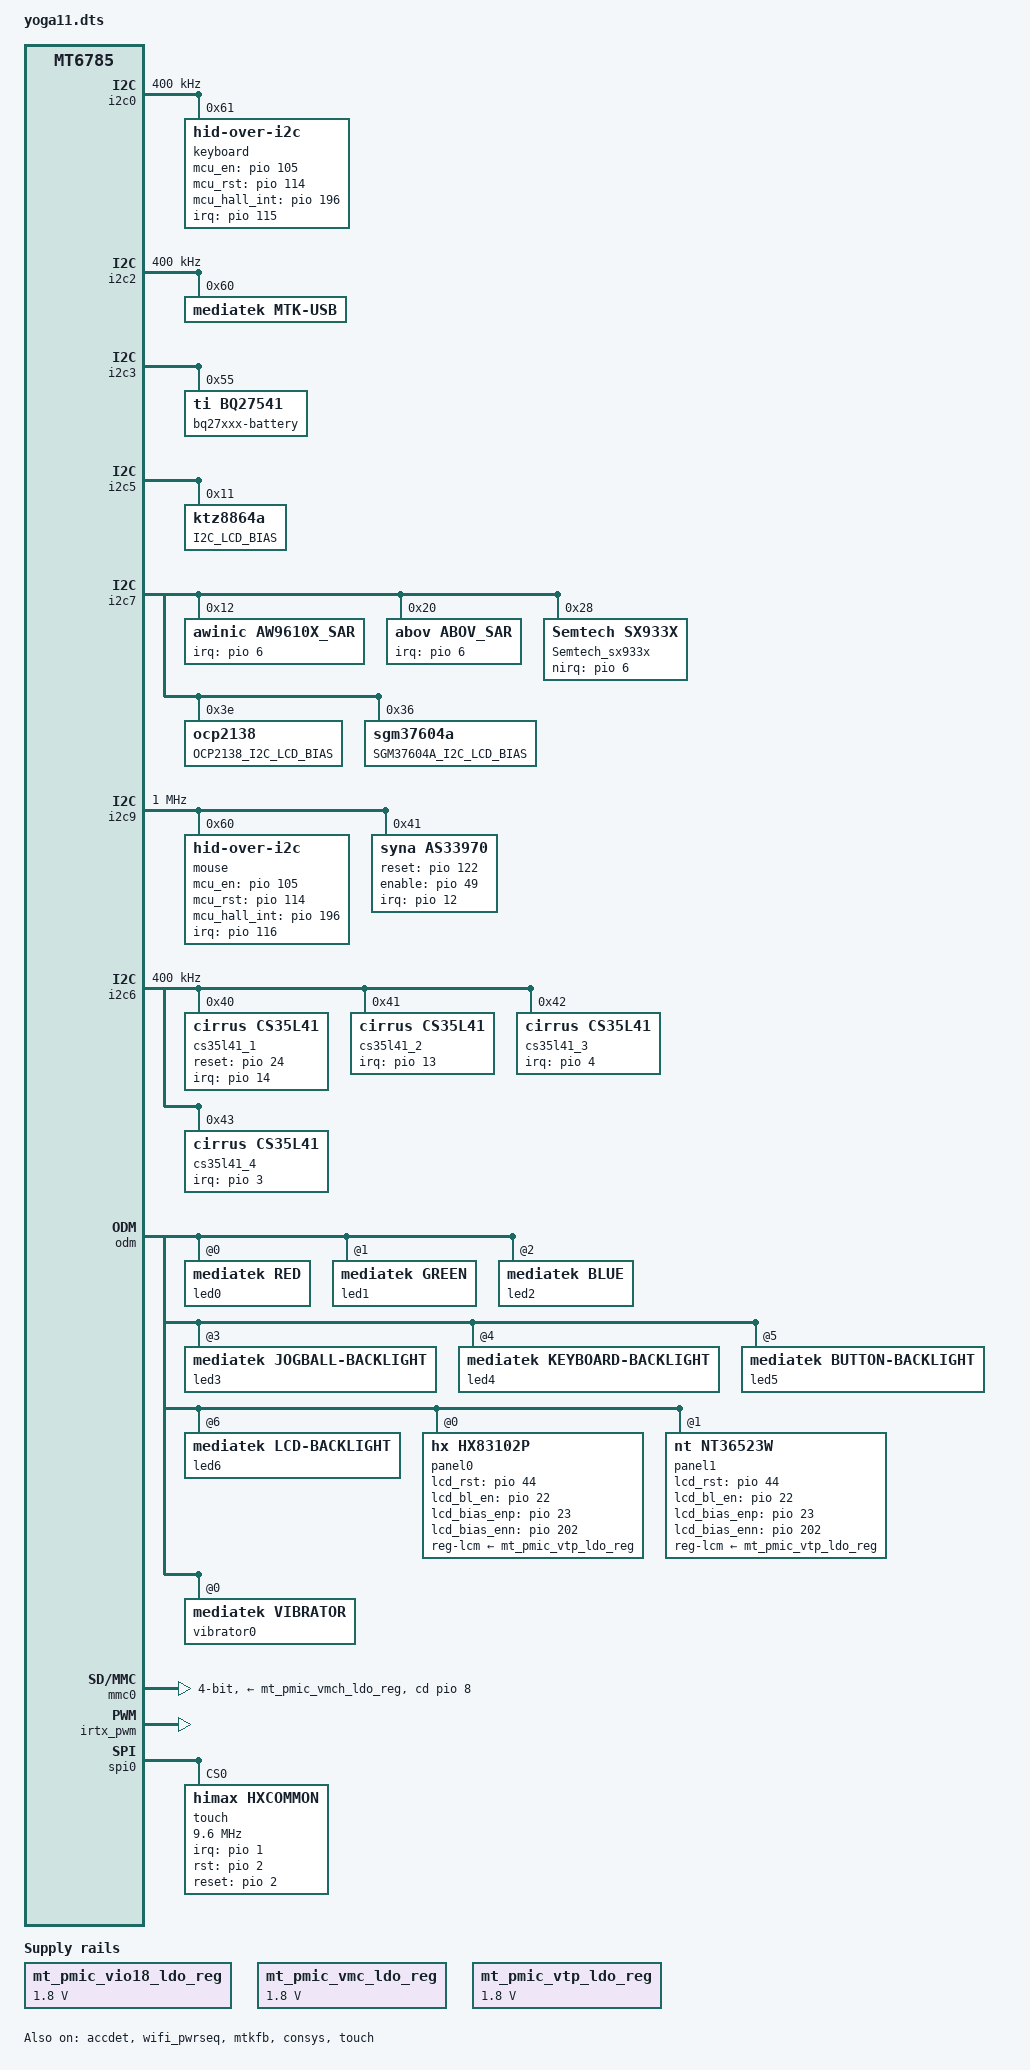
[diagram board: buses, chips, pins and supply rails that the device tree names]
/*
 * Copyright (C) 2015 MediaTek Inc.
 *
 * This program is free software: you can redistribute it and/or modify
 * it under the terms of the GNU General Public License version 2 as
 * published by the Free Software Foundation.
 *
 * This program is distributed in the hope that it will be useful,
 * but WITHOUT ANY WARRANTY; without even the implied warranty of
 * MERCHANTABILITY or FITNESS FOR A PARTICULAR PURPOSE. See the
 * GNU General Public License for more details.
 */
/dts-v1/;
/plugin/;
#include <dt-bindings/interrupt-controller/irq.h>
#include <dt-bindings/interrupt-controller/arm-gic.h>
#include <dt-bindings/pinctrl/mt6785-pinfunc.h>
#include <dt-bindings/clock/mt6785-clk.h>


&reserved_memory {
};

/* chosen */
&chosen {
	/* fpga may has no lk, we need to specify display info here */
	/* fb buffer is reserved using this dts by memory node above */

	atag,videolfb-fb_base_l = <0x7e605000>;
	atag,videolfb-fb_base_h = <0x0>;
	atag,videolfb-islcmfound = <1>;
	atag,videolfb-islcm_inited = <0>;
	atag,videolfb-fps= <6000>;
	atag,videolfb-vramSize= <0x017e8000>;
	atag,videolfb-lcmname=
		"hx83102p_fhdp_dsi_vdo_boe_drv";
};

&i2c0 {
	status="okay";
	clock-frequency = <400000>;
	keyboard@61 {
 		 compatible = "hid-over-i2c";
 		 reg = <0x61>;
 		 interrupt-parent = <&pio>;
		 interrupts = <115 IRQ_TYPE_EDGE_FALLING 115 0>;
 		 interrupt-names = "keyboard_kb_irq";
 		 hid-descr-addr =<0x0001>;
		 mcu_en_gpio = <&pio 105 0>;
		 mcu_rst_gpio = <&pio 114 0>;
		 mcu_hall_int_gpio = <&pio 196 0>;
		 post-power-on-delay-ms= <100>;
		 status = "okay";
 	};
};


&i2c2 {
	clock-frequency = <400000>;

	mtk-usb@60 {
		compatible = "mediatek,mtk-usb";
		reg = <0x60>;
		status = "okay";
	};
};

&i2c3 {
	bq27xxx-battery@55 {
		compatible = "ti,bq27541";
		reg = <0x55>;
	};
};

&lk_charger {
	compatible = "mediatek,lk_charger";
	fast_charge_voltage = <3000000>;
};

&charger {
	compatible = "mediatek,charger";
	/* PE */
	ta_12v_support;
	/* PD */
	pd_vbus_upper_bound = <11000000>;
};

&i2c5 {

	I2C_LCD_BIAS@11 {
		compatible = "ktz8864a" ;
		reg = <0x11> ;
		status = "okay" ;
	};
};


&i2c7 {
	aw9610x_sar@12 {
		compatible = "awinic,aw9610x_sar";
		reg = <0x12>;
		irq-gpio = <&pio 6 0x0>;
		chip_name = "AW96105";
		aw9610x,using-firmware;
		aw9610x,firmware_name = "aw9610x_wifi";
		status = "okay";
	};
	abov_sar@20 {
		compatible = "abov,abov_sar";
		reg = <0x20>;
		irq-gpio = <&pio 6 0x0>;        //interrup gpio number,based on actual circuit configuration
		reg_array_len = <0x03>;
		reg_array_val = <0x07 0x00 0x08 0x1B 0xFB 0x01>;
		cap,use_channel_ch0 = <0x00>;
		cap,use_channel_ch1 = <0x01>;
		cap,firmware_name = "AbovCapSenseWifi";  //firmware name,need pused AbovCapSense.BIN into /vendor/firmware/
		cap,channel_number = <0x02>;
		status = "okay";
	};
	Semtech_sx933x@28 {
		compatible = "Semtech,sx933x";
		reg = <0x28>;
		Semtech,nirq-gpio = <&pio 6 0x0>;
		/*use PH3/4 as the reference sensor*/
		/* set it to 0xff if the ref-phases-x is not used*/
		Semtech,ref-phases-a = <3>;
		Semtech,ref-phases-b = <4>;
		Semtech,reg-num = <85>;
		Semtech,reg-init = /bits/ 32 <
		0x8020 0x001F0000
		0x4004 0x00000070
		0x4008 0x00000000
		0x4054 0x00000400
		0x42C0 0x08000000
		0x42C4 0x0000003F
		0x800C 0x00000000
		0x8010 0x00000000
		0x8014 0x00000000
		0x8018 0x00000000
		0x801C 0x00000032
		0x8024 0x20000A8E
		0x8028 0x3FFE82E5
		0x802C 0x20000A8E
		0x8030 0x3FF7825F
		0x8034 0x20000A8E
		0x8038 0x3FBF82C4
		0x803C 0x20000A8E
		0x8040 0x3DFF8267
		0x8044 0x20000A8E
		0x8048 0x2FFF82E8
		0x804C 0x300004D4
		0x8050 0x00000000
		0x8054 0x0610FF00
		0x8058 0x20600018
		0x805C 0x2AD67000
		0x8060 0x00000000
		0x8064 0x00000000
		0x8068 0x00000000
		0x806C 0x00000000
		0x8070 0x00000000
		0x8074 0x10151C05
		0x8078 0x20600A0C
		0x807C 0x15EB8000
		0x8080 0x00000000
		0x8084 0x00000000
		0x8088 0x00000000
		0x808C 0x26002600
		0x8090 0x00010000
		0x8094 0x10252005
		0x8098 0x20600A0C
		0x809C 0x15EB8000
		0x80A0 0x00000000
		0x80A4 0x00000000
		0x80A8 0x00000000
		0x80AC 0x00270027
		0x80B0 0x00020000
		0x80B4 0x0650FF00
		0x80B8 0x20600018
		0x80BC 0x2AD67000
		0x80C0 0x00000000
		0x80C4 0x00000000
		0x80C8 0x00000000
		0x80CC 0x00000000
		0x80D0 0x00000000
		0x80D4 0x06500000
		0x80D8 0x20600018
		0x80DC 0x2AD67000
		0x80E0 0x00000000
		0x80E4 0x00000000
		0x80E8 0x00000000
		0x80EC 0x00000000
		0x80F0 0x00000000
		0x80F4 0x00100000
		0x80F8 0x20600C00
		0x80FC 0x00000000
		0x8100 0x00000000
		0x8104 0x00000000
		0x8108 0x00000000
		0x810C 0x00000000
		0x8110 0x00000000
		0x8124 0x04000004
		0x8128 0x04000003
		0x812C 0x00000000
		0x8130 0x00000000
		0x8134 0x00000000
		0x8138 0x00000000
		0x813C 0x00000000
		0x8140 0x00000000
		0x8144 0x00000000
		0x8148 0x00000000
		0x814C 0x00000000
		0x81A4 0x01D40010
		0x8020 0x001E001E
		0x4280 0x0000000F>;
	};
	OCP2138_I2C_LCD_BIAS@3E {
		compatible = "ocp2138" ;
		reg = <0x3E> ;
		status = "okay" ;
	};
	SGM37604A_I2C_LCD_BIAS@36 {
		compatible = "sgm37604a" ;
		reg = <0x36> ;
		status = "okay" ;
	};
};

&i2c9 {
	clock-frequency = <400000>;

	mouse@60 {
 		 compatible = "hid-over-i2c";
 		 reg = <0x60>;
		 mcu_en_gpio = <&pio 105 0>;
		 mcu_rst_gpio = <&pio 114 0>;
		 mcu_hall_int_gpio = <&pio 196 0>;
 		 interrupt-parent = <&pio>;
		 interrupts = <116 IRQ_TYPE_EDGE_FALLING 116 0>;
 		 interrupt-names = "keyboard_tp_irq";
 		 hid-descr-addr =<0x0001>;
		 post-power-on-delay-ms= <100>;
		 status = "okay";
	};
};


&i2c9 {
	clock-frequency = <1000000>;
	as33970@41 {
		compatible = "syna,as33970";
		reg = <0x41>;
		reset-gpios = <&pio 122 0x0>;
		enable-gpio = <&pio 49 0x0>;
		irq-gpios = <&pio 12 0x0>;
		status = "okay";
	};
};


&i2c6 {
	clock-frequency = <400000>;

	status="okay";

	/* Speaker 1st Amp */
	/*U2401  ---->  40*/
	cs35l41_1: cs35l41@40 {
		compatible = "cirrus,cs35l41";
		reg = <0x40>;

		reset-gpios = <&pio 24 0>;
		interrupt-parent = <&pio>;
		interrupts = <14 IRQ_TYPE_LEVEL_LOW 14 0>;
		interrupt-controller;
		#interrupt-cells = <2>;
		interrupt-names = "cs35l41_1_irq";

		pinctrl-names="default";
		pinctrl-0=<&cs35l41_1_irq_default>, <&cs35l41_reset_default>;

		cirrus,boost-peak-milliamp = <4500>;
		cirrus,boost-ind-nanohenry = <1000>;
		cirrus,boost-cap-microfarad = <15>;
		cirrus,asp-sdout-hiz = <0x3>;
		cirrus,fast-switch = "spk1_fast_switch1.txt", "spk1_fast_switch2.txt", "spk1_fast_switch3.txt", "spk1_fast_switch4.txt";
		cirrus,runtime-channel-switch;

		cirrus,gpio-config2 {
			cirrus,gpio-type = <1>; /* 0 indicate gpio, 1 indicate interrupt */
			cirrus,gpio-src-select = <0x4>;
			cirrus,gpio-output-enable;
		};
		adsps {
			#address-cells = <1>;
			#size-cells = <0>;
			adsp@2b80000 {
				reg = <0x2b80000>;
				firmware {
					protection {
						cirrus,full-name;
						cirrus,wmfw-file = "cs35l41-dsp1-spk-prot.wmfw";
						cirrus,bin-file = "cs35l41-dsp1-spk-prot1.bin";
					};
					calibration {
						cirrus,full-name;
						cirrus,wmfw-file = "cs35l41-dsp1-spk-cali.wmfw";
						cirrus,bin-file = "cs35l41-dsp1-spk-cali1.bin";
					};
				};
			};
		};
	};

	/* Speaker 2nd Amp */
	/*U2404 --->  41*/
	cs35l41_2: cs35l41@41 {
		compatible = "cirrus,cs35l41";
		reg = <0x41>;

		//reset-gpios = <&pio 24 0>;
		interrupt-parent = <&pio>;
		interrupts = <13 IRQ_TYPE_LEVEL_LOW 13 0>;
		interrupt-controller;
		#interrupt-cells = <2>;
		interrupt-names = "cs35l41_2_irq";

		pinctrl-names="default";
		pinctrl-0=<&cs35l41_2_irq_default>;

		cirrus,boost-peak-milliamp = <4500>;
		cirrus,boost-ind-nanohenry = <1000>;
		cirrus,boost-cap-microfarad = <15>;
		cirrus,asp-sdout-hiz = <0x3>;
		cirrus,fast-switch = "spk2_fast_switch1.txt", "spk2_fast_switch2.txt", "spk2_fast_switch3.txt", "spk2_fast_switch4.txt";
		cirrus,runtime-channel-switch;

		cirrus,gpio-config2 {
			cirrus,gpio-type = <1>; /* 0 indicate gpio, 1 indicate interrupt */
			cirrus,gpio-src-select = <0x4>;
			cirrus,gpio-output-enable;
		};
		adsps {
			#address-cells = <1>;
			#size-cells = <0>;
			adsp@2b80000 {
				reg = <0x2b80000>;
				firmware {
					protection {
						cirrus,full-name;
						cirrus,wmfw-file = "cs35l41-dsp1-spk-prot.wmfw";
						cirrus,bin-file = "cs35l41-dsp1-spk-prot2.bin";
					};
					calibration {
						cirrus,full-name;
						cirrus,wmfw-file = "cs35l41-dsp1-spk-cali.wmfw";
						cirrus,bin-file = "cs35l41-dsp1-spk-cali2.bin";
					};
				};
			};
		};
	};

	/* Speaker 3rd Amp */
	/*u2402 ----->  42*/
	cs35l41_3: cs35l41@42 {
		compatible = "cirrus,cs35l41";
		reg = <0x42>;

		//reset-gpios = <&pio 24 0>;
		interrupt-parent = <&pio>;
		interrupts = <4 IRQ_TYPE_LEVEL_LOW 4 0>;
		interrupt-controller;
		#interrupt-cells = <2>;
		interrupt-names = "cs35l41_3_irq";

		pinctrl-names="default";
		pinctrl-0=<&cs35l41_3_irq_default>;
		cirrus,boost-peak-milliamp = <4500>;
		cirrus,boost-ind-nanohenry = <1000>;
		cirrus,boost-cap-microfarad = <15>;
		cirrus,asp-sdout-hiz = <0x3>;
		cirrus,fast-switch = "spk3_fast_switch1.txt", "spk3_fast_switch2.txt", "spk3_fast_switch3.txt", "spk3_fast_switch4.txt";
		cirrus,runtime-channel-switch;

		cirrus,gpio-config2 {
			cirrus,gpio-type = <1>; /* 0 indicate gpio, 1 indicate interrupt */
			cirrus,gpio-src-select = <0x4>;
			cirrus,gpio-output-enable;
		};
		adsps {
			#address-cells = <1>;
			#size-cells = <0>;
			adsp@2b80000 {
				reg = <0x2b80000>;
				firmware {
					protection {
						cirrus,full-name;
						cirrus,wmfw-file = "cs35l41-dsp1-spk-prot.wmfw";
						cirrus,bin-file = "cs35l41-dsp1-spk-prot3.bin";
					};
					calibration {
						cirrus,full-name;
						cirrus,wmfw-file = "cs35l41-dsp1-spk-cali.wmfw";
						cirrus,bin-file = "cs35l41-dsp1-spk-cali3.bin";
					};
				};
			};
		};
	};

	/* Speaker 4th Amp */
	/*U2403  ---->  43*/
	cs35l41_4: cs35l41@43 {
		compatible = "cirrus,cs35l41";
		reg = <0x43>;

		//reset-gpios = <&pio 24 0>;
		interrupt-parent = <&pio>;
		interrupts = <3 IRQ_TYPE_LEVEL_LOW 3 0>;
		interrupt-controller;
		#interrupt-cells = <2>;
		interrupt-names = "cs35l41_4_irq";

		pinctrl-names="default";
		pinctrl-0=<&cs35l41_4_irq_default>;
		cirrus,boost-peak-milliamp = <4500>;
		cirrus,boost-ind-nanohenry = <1000>;
		cirrus,boost-cap-microfarad = <15>;
		cirrus,asp-sdout-hiz = <0x3>;
		cirrus,fast-switch = "spk4_fast_switch1.txt", "spk4_fast_switch2.txt", "spk4_fast_switch3.txt", "spk4_fast_switch4.txt";
		cirrus,runtime-channel-switch;

		cirrus,gpio-config2 {
			cirrus,gpio-type = <1>; /* 0 indicate gpio, 1 indicate interrupt */
			cirrus,gpio-src-select = <0x4>;
			cirrus,gpio-output-enable;
		};
		adsps {
			#address-cells = <1>;
			#size-cells = <0>;
			adsp@2b80000 {
				reg = <0x2b80000>;
				firmware {
					protection {
						cirrus,full-name;
						cirrus,wmfw-file = "cs35l41-dsp1-spk-prot.wmfw";
						cirrus,bin-file = "cs35l41-dsp1-spk-prot4.bin";
					};
					calibration {
						cirrus,full-name;
						cirrus,wmfw-file = "cs35l41-dsp1-spk-cali.wmfw";
						cirrus,bin-file = "cs35l41-dsp1-spk-cali4.bin";
					};
				};
			};
		};
	};
};

&pio {
	cs35l41_1_irq_default: cs35l41_1_irq_default {
		pins_cmd_dat {
			pinmux = <PINMUX_GPIO14__FUNC_GPIO14>;
			slew-rate = <0>;
			bias-pull-up = <00>;
		};
	};

	cs35l41_2_irq_default: cs35l41_2_irq_default {
		pins_cmd_dat {
			pinmux = <PINMUX_GPIO13__FUNC_GPIO13>;
			slew-rate = <0>;
			bias-pull-up = <00>;
		};
	};

	cs35l41_3_irq_default: cs35l41_3_irq_default {
		pins_cmd_dat {
			pinmux = <PINMUX_GPIO4__FUNC_GPIO4>;
			slew-rate = <0>;
			bias-pull-up = <00>;
		};
	};

	cs35l41_4_irq_default: cs35l41_4_irq_default {
		pins_cmd_dat {
			pinmux = <PINMUX_GPIO3__FUNC_GPIO3>;
			slew-rate = <0>;
			bias-pull-up = <00>;
		};
	};

	cs35l41_reset_default: cs35l41_reset_default {
		pins_cmd_dat {
			pinmux = <PINMUX_GPIO24__FUNC_GPIO24>;
			slew-rate = <1>;
			bias-pull-up = <00>;
		};
	};
};

&sound{
	cirrus,prince-max-devs = <4>;
	cirrus,prince-devs = <&cs35l41_1>, <&cs35l41_2>, <&cs35l41_3>, <&cs35l41_4>;
	cirrus,prince-dev-prefix = "SPK1", "SPK2", "SPK3", "SPK4";
};

/* accdet start */
&accdet {
	/* accdet micbias voltage: 0x09:2.85v 0x08:2.8v 0x07,
	 * 2.7v;0x05,2.5v;0x02,1.9v
	 */
	accdet-mic-vol = <8>;
	/* accdet pwm_width, pwm_thresh, fall_delay, rise_delay
	 * debounce0, debounce1, debounce3, debounce4
	 * eint pwm_width, eint pwm_thresh
	 * eint deb(debounce0, debounce1, debounce2, debounce3), inv_debounce
	 */
	headset-mode-setting = <0x500 0x500 1 0x1f0
				0x800 0x800 0x20 0x44
				0x4 0x1
				0x5 0x3 0x3 0x5 0xe>;
	accdet-plugout-debounce = <1>;
	/*1:ACC mode, 2:low cost without in bias, 6:low cost with in bias*/
	accdet-mic-mode = <2>;
	/*0--MD_MAX--UP_MAX--DW_MAX*/
	headset-three-key-threshold = <0 80 220 400>;
	headset-three-key-threshold-CDD = <0 121 192 600>;
	/*0--MD_MAX--VOICE_MAX--UP_MAX--DW_MAX*/
	headset-four-key-threshold = <0 58 121 192 400>;

	/* select VTH to 2v and 500k, use internal resitance */
	eint_use_ext_res = <0>;
	status = "okay";
};
/* accdet end */


/* audio gpio start */
/* AUDIO GPIO standardization */
/*
&sound {
	pinctrl-names = "ext_hp_amp_on",
			"ext_hp_amp_off";
	pinctrl-0 = <&ext_hp_amp_on>;
	pinctrl-1 = <&ext_hp_amp_off>;
	status = "okay";
};
*/
&wifi_pwrseq {
	status = "okay";
	pinctrl-names = "default";
	pinctrl-0 = <&wifi_pins_pwrseq>;

	reset-gpios = <&pio 99 1>;
};

/*&msdc1 {
	compatible = "mediatek,mt8185-sdio";
	reg = <0x0 0x11240000 0x0 0x10000>,
	    <0 0x11e10000 0 0x1000>;
	clocks = <&infracfg_ao INFRACFG_AO_MSDC1_SCK_CG>,
	       <&infracfg_ao INFRACFG_AO_MSDC1_CG>;
	clock-names = "source", "hclk";
	status = "okay";
	eint-gpios = <&pio 139 0>;
	bus-width = <4>;
	max-frequency = <200000000>;
	cap-sd-highspeed;
	sd-uhs-sdr50;
	sd-uhs-sdr104;
	pinctrl-names = "state_eint", "default", "state_uhs", "state_dat1";
	pinctrl-0 = <&sdio_pins_eint>;
	pinctrl-1 = <&sdio_pins_default>;
	pinctrl-2 = <&sdio_pins_uhs>;
	pinctrl-3 = <&sdio_pins_dat1>;
	keep-power-in-suspend;
	enable-sdio-wakeup;
	cap-sdio-irq;
	no-sdio-incr1;
	non-removable;
	vmmc-supply = <&mt_pmic_vmch_ldo_reg>;
	vqmmc-supply = <&mt_pmic_vmc_ldo_reg>;
	mmc-pwrseq = <&wifi_pwrseq>;
};*/

&mt_pmic_vcn18_ldo_reg {
	regulator-always-on;
};

&mt_pmic_vio18_ldo_reg {
	regulator-always-on;
	regulator-min-microvolt = <1800000>;
	regulator-max-microvolt = <1800000>;
};

&mt_pmic_vmc_ldo_reg {
	regulator-min-microvolt = <1800000>;
	regulator-max-microvolt = <1800000>;
};

&pio {
	sdio_pins_eint: dat1_eint {
		pins_dat1 {
			pinmux = <PINMUX_GPIO139__FUNC_GPIO139>;
			input_enable;
			slew-rate = <0>;
			bias-pull-up = <MTK_PUPD_SET_R1R0_01>;
		};
	};

	sdio_pins_default: sdiodefault {
		pins_cmd_dat {
			pinmux = <PINMUX_GPIO135__FUNC_MSDC1_CMD>,
			       <PINMUX_GPIO137__FUNC_MSDC1_DAT0>,
			       <PINMUX_GPIO139__FUNC_MSDC1_DAT1>,
			       <PINMUX_GPIO138__FUNC_MSDC1_DAT2>,
			       <PINMUX_GPIO136__FUNC_MSDC1_DAT3>;
			bias-pull-up = <MTK_PUPD_SET_R1R0_01>;
			drive-strength = <2>;
			output-high;
		};

		pins_clk {
			pinmux = <PINMUX_GPIO134__FUNC_MSDC1_CLK>;
			bias-pull-down = <MTK_PUPD_SET_R1R0_10>;
			drive-strength = <2>;
			output-low;
		};
	};

	sdio_pins_uhs: sdio@uhs {
		pins_cmd_dat {
			pinmux = <PINMUX_GPIO135__FUNC_MSDC1_CMD>,
			       <PINMUX_GPIO137__FUNC_MSDC1_DAT0>,
			       <PINMUX_GPIO139__FUNC_MSDC1_DAT1>,
			       <PINMUX_GPIO138__FUNC_MSDC1_DAT2>,
			       <PINMUX_GPIO136__FUNC_MSDC1_DAT3>;
			bias-pull-up = <MTK_PUPD_SET_R1R0_01>;
			drive-strength = <2>;
			output-high;
		};

		pins_clk {
			pinmux = <PINMUX_GPIO134__FUNC_MSDC1_CLK>;
			bias-pull-down = <MTK_PUPD_SET_R1R0_10>;
			drive-strength = <2>;
			output-low;
		};
	};

	sdio_pins_dat1: sdio_dat1 {
		pins_dat1 {
			pinmux = <PINMUX_GPIO139__FUNC_MSDC1_DAT1>;
			drive-strength = <2>;
			bias-pull-up = <MTK_PUPD_SET_R1R0_01>;
			output-high;
		};
	};

	wifi_pins_pwrseq: wifipwrseq {
		pins_wifi_enable {
			pinmux = <PINMUX_GPIO99__FUNC_GPIO99>;
			drive-strength = <MTK_DRIVE_4mA>;
			output-low;
		};
	};

	mediatek,mt7663-wifi {
		compatible = "mediatek,mt7663_wifi_ctrl";
		interrupt-parent = <&pio>;
		interrupts = <149 IRQ_TYPE_EDGE_FALLING 149 0>;
		status = "okay";
	};
};

&odm {
	led0:led@0 {
		compatible = "mediatek,red";
		led_mode = <0>;
		data = <1>;
		pwm_config = <0 0 0 0 0>;
	};
	led1:led@1 {
		compatible = "mediatek,green";
		led_mode = <0>;
		data = <1>;
		pwm_config = <0 0 0 0 0>;
	};
	led2:led@2 {
		compatible = "mediatek,blue";
		led_mode = <0>;
		data = <1>;
		pwm_config = <0 0 0 0 0>;
	};
	led3:led@3 {
		compatible = "mediatek,jogball-backlight";
		led_mode = <0>;
		data = <1>;
		pwm_config = <0 0 0 0 0>;
	};
	led4:led@4 {
		compatible = "mediatek,keyboard-backlight";
		led_mode = <0>;
		data = <1>;
		pwm_config = <0 0 0 0 0>;
	};
	led5:led@5 {
		compatible = "mediatek,button-backlight";
		led_mode = <0>;
		data = <1>;
		pwm_config = <0 0 0 0 0>;
	};
	led6:led@6 {
		compatible = "mediatek,lcd-backlight";
		led_mode = <4>;
		data = <1>;
		pwm_config = <0 1 0 0 0>;
	};
	usb_c_pinctrl:usb_c_pinctrl {
		//compatible = "mediatek,usb_c_pinctrl";
	};
	panel0: panel@0 {
		compatible = "hx,hx83102p";
		gpio_lcd_rst = <&pio 44 0>;
		gpio_lcd_bl_en = <&pio 22 0>;
		gpio_lcd_bias_enp = <&pio 23 0>;
		gpio_lcd_bias_enn = <&pio 202 0>;
		reg-lcm-supply = <&mt_pmic_vtp_ldo_reg>;
		status = "okay";
	};
        panel1: panel@1 {
                compatible = "nt,nt36523w";
                gpio_lcd_rst = <&pio 44 0>;
                gpio_lcd_bl_en = <&pio 22 0>;
                gpio_lcd_bias_enp = <&pio 23 0>;
                gpio_lcd_bias_enn = <&pio 202 0>;
                reg-lcm-supply = <&mt_pmic_vtp_ldo_reg>;
                status = "okay";
        };

	vibrator0:vibrator@0 {
		compatible = "mediatek,vibrator";
		vib_timer = <25>;
		vib_limit = <9>;
		vib_vol= <9>;
	};

};

/* DISPSYS GPIO standardization */
&pio {
	mtkfb_pins_lcd_bias_enp1: lcd_bias_enp1_gpio {
		pins_cmd_dat {
			pinmux = <PINMUX_GPIO23__FUNC_GPIO23>;
			slew-rate = <1>;
			output-high;
		};
	};

	mtkfb_pins_lcd_bias_enp0: lcd_bias_enp0_gpio {
		pins_cmd_dat {
			pinmux = <PINMUX_GPIO23__FUNC_GPIO23>;
			slew-rate = <1>;
			output-low;
		};
	};

	mtkfb_pins_lcd_bias_enn1: lcd_bias_enn1_gpio {
		pins_cmd_dat {
			pinmux = <PINMUX_GPIO202__FUNC_GPIO202>;
			slew-rate = <1>;
			output-high;
		};
	};

	mtkfb_pins_lcd_bias_enn0: lcd_bias_enn0_gpio {
		pins_cmd_dat {
			pinmux = <PINMUX_GPIO202__FUNC_GPIO202>;
			slew-rate = <1>;
			output-low;
		};
	};

	mtkfb_pins_lcm_rst_out1_gpio: lcm_rst_out1_gpio {
		pins_cmd_dat {
			pinmux = <PINMUX_GPIO44__FUNC_GPIO44>;
			slew-rate = <1>;
			output-high;
		};
	};

	mtkfb_pins_lcm_rst_out0_gpio: lcm_rst_out0_gpio {
		pins_cmd_dat {
			pinmux = <PINMUX_GPIO44__FUNC_GPIO44>;
			slew-rate = <1>;
			output-low;
		};
	};
	mtkfb_pins_lcm_dsi_te: lcm_dsi_te {
		pins_cmd_dat {
			pinmux = <PINMUX_GPIO43__FUNC_DSI_TE>;
		};
	};
};

&mt_pmic_vtp_ldo_reg {
	regulator-min-microvolt = <1800000>;
	regulator-max-microvolt = <1800000>;
};

&mtkfb {
	pinctrl-names = "lcd_bias_enp1_gpio", "lcd_bias_enp0_gpio",
		"lcd_bias_enn1_gpio", "lcd_bias_enn0_gpio",
		"lcm_rst_out1_gpio", "lcm_rst_out0_gpio",
		"mode_te_te";
	pinctrl-0 = <&mtkfb_pins_lcd_bias_enp1>;
	pinctrl-1 = <&mtkfb_pins_lcd_bias_enp0>;
	pinctrl-2 = <&mtkfb_pins_lcd_bias_enn1>;
	pinctrl-3 = <&mtkfb_pins_lcd_bias_enn0>;
	pinctrl-4 = <&mtkfb_pins_lcm_rst_out1_gpio>;
	pinctrl-5 = <&mtkfb_pins_lcm_rst_out0_gpio>;
	pinctrl-6 = <&mtkfb_pins_lcm_dsi_te>;
	status = "okay";
};

/* DISPSYS GPIO standardization end */
&mt6360_ldo {
	sdcard_hlact = <0>;
	sdcard_det_en = <0>;
};

&mt6360_pmu {
	mt6360,intr_gpio_num = <16>; /* direct defined GPIO num */
	mt6360,intr_gpio = <&pio 16 0x0>;
};

&mt6360_typec {
	mt6360pd,intr_gpio_num = <7>; /* direct defined GPIO num */
	mt6360pd,intr_gpio = <&pio 7 0x0>;
	mt6360pd,pcb_gpio = <&pio 5 0x0>;
	mt6360pd,pcb_gpio_num = <5>;
	mt6360pd,pcb_gpio_polarity = <1>;
};

/* USB SWITCH GPIO start */
&pio {
	usb_default: usb_default {
	};

	gpio_redriver_c1_init: c1_init {

	};

	gpio_redriver_c1_low: c1_low {

	};

	gpio_redriver_c1_hiz: c1_highz {

	};

	gpio_redriver_c1_high: c1_high {

	};

	gpio_redriver_c2_init: c2_init {
		pins_cmd_dat {
			pinmux = <PINMUX_GPIO30__FUNC_GPIO30>;
			slew-rate = <1>;
			output-low;
		};
	};

	gpio_redriver_c2_low: c2_low {
		pins_cmd_dat {
			pinmux = <PINMUX_GPIO30__FUNC_GPIO30>;
			slew-rate = <1>;
			output-low;
		};
	};

	gpio_redriver_c2_hiz: c2_highz {
		pins_cmd_dat {
			pinmux = <PINMUX_GPIO30__FUNC_GPIO30>;
			slew-rate= <0>;
			bias-disable;
		};
	};

	gpio_redriver_c2_high: c2_high {
		pins_cmd_dat {
			pinmux = <PINMUX_GPIO30__FUNC_GPIO30>;
			slew-rate = <1>;
			output-high;
		};
	};

	gpio_u3_switch_sel1: u3_sw_sel1 {
		pins_cmd_dat {
			pinmux = <PINMUX_GPIO32__FUNC_GPIO32>;
			slew-rate = <1>;
			output-low;
		};
	};

	gpio_u3_switch_sel2: u3_sw_sel2 {
		pins_cmd_dat {
			pinmux = <PINMUX_GPIO32__FUNC_GPIO32>;
			slew-rate = <1>;
			output-high;
		};
	};

	gpio_u3_switch_enable: u3_sw_en {
	};

	gpio_u3_switch_disable: u3_sw_dis {
	};
};

&usb_c_pinctrl {
	pinctrl-names = "usb_default",
		"redrv_c1_init",
		"redrv_c1_low",
		"redrv_c1_hiz",
		"redrv_c1_high",
		"redrv_c2_init",
		"redrv_c2_low",
		"redrv_c2_hiz",
		"redrv_c2_high",
		"switch_sel1",
		"switch_sel2",
		"switch_enable",
		"switch_disable";

	pinctrl-0 = <&usb_default>;
	pinctrl-1 = <&gpio_redriver_c1_init>;
	pinctrl-2 = <&gpio_redriver_c1_low>;
	pinctrl-3 = <&gpio_redriver_c1_hiz>;
	pinctrl-4 = <&gpio_redriver_c1_high>;
	pinctrl-5 = <&gpio_redriver_c2_init>;
	pinctrl-6 = <&gpio_redriver_c2_low>;
	pinctrl-7 = <&gpio_redriver_c2_hiz>;
	pinctrl-8 = <&gpio_redriver_c2_high>;
	pinctrl-9 = <&gpio_u3_switch_sel1>;
	pinctrl-10 = <&gpio_u3_switch_sel2>;
	pinctrl-11 = <&gpio_u3_switch_enable>;
	pinctrl-12 = <&gpio_u3_switch_disable>;
	status = "disable";

	usb_switch-data {
		en_pin_num = <0>;
		en_pin_val = <0>;
		sel_pin_num = <32>;
		sel_pin_val = <1>;
		c1_pin_num = <31>;
		c1_pin_val = <2>;
		c2_pin_num = <30>;
		c2_pin_val = <1>;
	};
};
/* USB SWITCH GPIO end */

&pio {
	mmc0_pins_default: mmc0default {
		   pins_cmd_dat {
			   pinmux = <PINMUX_GPIO168__FUNC_MSDC0_DAT0>,
				  <PINMUX_GPIO172__FUNC_MSDC0_DAT1>,
				  <PINMUX_GPIO169__FUNC_MSDC0_DAT2>,
				  <PINMUX_GPIO177__FUNC_MSDC0_DAT3>,
				  <PINMUX_GPIO167__FUNC_MSDC0_CMD>;
			   drive-strength = <MTK_DRIVE_4mA>;
			   input-enable;
			   bias-pull-up = <MTK_PUPD_SET_R1R0_01>;
		   };

		   pins_clk {
			   drive-strength = <MTK_DRIVE_4mA>;
			   pinmux = <PINMUX_GPIO176__FUNC_MSDC0_CLK>;
			   bias-pull-down = <MTK_PUPD_SET_R1R0_10>;
		   };

		   pins_shift {
			   pinmux = <PINMUX_GPIO47__FUNC_GPIO47>;
			   output-low;
		   };
	};

	mmc0_pins_uhs: mmc0@0 {
		   pins_cmd_dat {
			   pinmux = <PINMUX_GPIO168__FUNC_MSDC0_DAT0>,
				  <PINMUX_GPIO172__FUNC_MSDC0_DAT1>,
				  <PINMUX_GPIO169__FUNC_MSDC0_DAT2>,
				  <PINMUX_GPIO177__FUNC_MSDC0_DAT3>,
				  <PINMUX_GPIO167__FUNC_MSDC0_CMD>;
			   drive-strength = <MTK_DRIVE_4mA>;
			   input-enable;
			   bias-pull-up = <MTK_PUPD_SET_R1R0_01>;
		   };

		   pins_clk {
			   drive-strength = <MTK_DRIVE_4mA>;
			   pinmux = <PINMUX_GPIO176__FUNC_MSDC0_CLK>;
			   bias-pull-down = <MTK_PUPD_SET_R1R0_10>;
		   };

		   pins_shift {
			   pinmux = <PINMUX_GPIO47__FUNC_GPIO47>;
			   output-high;
		   };
	};
};

&mmc0 {
	pinctrl-names = "default", "state_uhs";
	pinctrl-0 = <&mmc0_pins_default>;
	pinctrl-1 = <&mmc0_pins_uhs>;
	status = "okay";
	bus-width = <4>;
	max-frequency = <200000000>;
	cd-gpios = <&pio 8 0>;
	cap-sd-highspeed;
	sd-uhs-sdr12;
	sd-uhs-sdr25;
	sd-uhs-sdr50;
	sd-uhs-sdr104;
	no-sdio;
	no-mmc;
	vmmc-supply = <&mt_pmic_vmch_ldo_reg>;
	vqmmc-supply = <&mt_pmic_vfp_ldo_reg>;
};

/* CONSYS GPIO standardization */
&pio {
	consys_pins_default: consys_default {
	};
	gpslna_pins_init: gpslna@0 {
		pins_cmd_dat {
			pinmux = <PINMUX_GPIO155__FUNC_GPIO155>;
			slew-rate = <0>;
			bias-disable;
			output-low;
		};
	};
	gpslna_pins_oh: gpslna@1 {
		pins_cmd_dat {
			pinmux = <PINMUX_GPIO155__FUNC_GPIO155>;
			slew-rate = <1>;
			output-high;
		};
	};
	gpslna_pins_ol: gpslna@2 {
		pins_cmd_dat {
			pinmux = <PINMUX_GPIO155__FUNC_GPIO155>;
			slew-rate = <1>;
			output-low;
		};
	};
};
&consys {
	pinctrl-names = "default", "gps_lna_state_init",
		"gps_lna_state_oh", "gps_lna_state_ol";
	pinctrl-0 = <&consys_pins_default>;
	pinctrl-1 = <&gpslna_pins_init>;
	pinctrl-2 = <&gpslna_pins_oh>;
	pinctrl-3 = <&gpslna_pins_ol>;
	status = "okay";
};
/* CONSYS end */

/* IRTX GPIO Start */
&irtx_pwm {
	pinctrl-names = "irtx_gpio_led_default", "irtx_gpio_led_set";
	pinctrl-0 = <&irtx_gpio_led_default>;
	pinctrl-1 = <&irtx_gpio_led_set>;
	status = "okay";
};
&pio {
	/* IRTX GPIO Settings -Start */
	/* default: GPIO0, output, high */
	irtx_gpio_led_default:irtx_gpio_led_def@gpio26 {
		pins_cmd_dat {
			pinmux = <PINMUX_GPIO26__FUNC_GPIO26>;
			slew-rate = <1>;
			bias-disable;
			output-low;
			input-schmitt-enable = <0>;
		};
	};

	irtx_gpio_led_set:irtx_gpio_led_set@gpio26 {
		pins_cmd_dat {
			pinmux = <PINMUX_GPIO26__FUNC_PWM_0>;
			slew-rate = <1>;
			output-high;
		};
	};
}; /* IRTX GPIO Settings -End */

&i2c5 {
	I2C_LCD_BIAS@11 {
		compatible = "ktz8864a" ;
		reg = <0x11> ;
		status = "okay" ;
	};
};

/* TOUCH start */
&pio {
	ctp_pins_default: pins_default {
	};
	ctp_pins_eint_as_int: eint@0 {
		pins_cmd_dat {
			pinmux = <PINMUX_GPIO1__FUNC_GPIO1>;
			slew-rate = <0>;
			bias-disable;
		};
	};
	ctp_pins_eint_output0: eintoutput0 {
		pins_cmd_dat {
			pinmux = <PINMUX_GPIO1__FUNC_GPIO1>;
			slew-rate = <1>;
			output-low;
		};
	};
	ctp_pins_eint_output1: eintoutput1 {
		pins_cmd_dat {
			pinmux = <PINMUX_GPIO1__FUNC_GPIO1>;
			slew-rate = <1>;
			output-high;
		};
	};
	ctp_pins_rst_output0: rstoutput0 {
		pins_cmd_dat {
			pinmux = <PINMUX_GPIO2__FUNC_GPIO2>;
			slew-rate = <1>;
			output-low;
		};
	};
	ctp_pins_rst_output1: rstoutput1 {
		pins_cmd_dat {
			pinmux = <PINMUX_GPIO2__FUNC_GPIO2>;
			slew-rate = <1>;
			output-high;
		};
	};
	ctp_pins_cs_output0: csoutput0 {
		pins_cmd_dat {
			pinmux = <PINMUX_GPIO19__FUNC_GPIO19>;
			slew-rate = <1>;
			output-low;
		};
	};
	ctp_pins_cs_output1: csoutput1 {
		pins_cmd_dat {
			pinmux = <PINMUX_GPIO19__FUNC_GPIO19>;
			slew-rate = <1>;
			output-high;
		};
	};
	ctp_pins_spi_mode: spimode_default {
		pins_cmd_dat {
			pinmux = <PINMUX_GPIO17__FUNC_SPI0_A_MI>,
				<PINMUX_GPIO18__FUNC_SPI0_A_MO>,
				<PINMUX_GPIO19__FUNC_SPI0_A_CSB>,
				<PINMUX_GPIO20__FUNC_SPI0_A_CLK>;
			drive-strength=<4>;
		};
	};
};

&spi0 {
	#address-cells = <1>;
	#size-cells = <0>;
	status = "okay";
	touch@0 {
		compatible = "himax,hxcommon","novatek,NVT-ts-spi";
		reg = <0>;
		spi-max-frequency = <9600000>;	//4800000,9600000,15000000,19200000

/* himax device tree node */
		spi-cpha = <1>;
		spi-cpol = <1>;
		interrupt-parent = <&pio>;
		himax,panel-coords = <0 1200 0 2000>;
		himax,display-cords = <0 1200 0 2000>;
		himax,irq-gpio = <&pio 1 0>;
		himax,rst-gpio = <&pio 2 0>;
		report_type = <1>;

/* Novatek device tree node */

		novatek,reset-gpio = <&pio 2 0>;
		novatek,irq-gpio = <&pio 1 0>;

		novatek,pen-support;
		novatek,wgp-stylus;

		/*  523 */
		novatek,swrst-n8-addr = <0x03F0FE>;
		novatek,spi-rd-fast-addr = <0x03F310>;

		/* MP */
		novatek,mp-support-dt;

		/*for Lenovo_yoga11 Longcheer_P530 BOE10.95 LianChuang module*/
		novatek-mp-criteria-603B@0 {
			#address-cells = <1>;
			#size-cells = <0>;
			compatible = "novatek-mp-criteria-603B";

			/* MP Config */
			IC_X_CFG_SIZE = <32>;
			IC_Y_CFG_SIZE = <48>;
			IC_KEY_CFG_SIZE = <4>;
			X_Channel = <32>;
			Y_Channel = <48>;
			AIN_X = <0 1 2 3 4 5 6 7 8 9 10 11 12 13 14 15 16 17 18 19 20 21 22 23 24 25 26 27 28 29 30 31>;
			AIN_Y = <0 1 2 3 4 5 6 7 8 9 10 11 12 13 14 15 16 17 18 19 20 21 22 23 24 25 26 27 28 29 30 31 32 33 34 35 36 37 38 39 40 41 42 43 44 45 46 47>;
			AIN_KEY = <0 1 2 0xFF>;

			/* MP Criteria */
			PS_Config_Lmt_Short_Rawdata_P = <
				14008 14008 14008 14008 14008 14008 14008 14008 14008 14008 14008 14008 14008 14008 14008 14008 14008 14008 14008 14008 14008 14008 14008 14008 14008 14008 14008 14008 14008 14008 14008 14008
				14008 14008 14008 14008 14008 14008 14008 14008 14008 14008 14008 14008 14008 14008 14008 14008 14008 14008 14008 14008 14008 14008 14008 14008 14008 14008 14008 14008 14008 14008 14008 14008
				14008 14008 14008 14008 14008 14008 14008 14008 14008 14008 14008 14008 14008 14008 14008 14008 14008 14008 14008 14008 14008 14008 14008 14008 14008 14008 14008 14008 14008 14008 14008 14008
				14008 14008 14008 14008 14008 14008 14008 14008 14008 14008 14008 14008 14008 14008 14008 14008 14008 14008 14008 14008 14008 14008 14008 14008 14008 14008 14008 14008 14008 14008 14008 14008
				14008 14008 14008 14008 14008 14008 14008 14008 14008 14008 14008 14008 14008 14008 14008 14008 14008 14008 14008 14008 14008 14008 14008 14008 14008 14008 14008 14008 14008 14008 14008 14008
				14008 14008 14008 14008 14008 14008 14008 14008 14008 14008 14008 14008 14008 14008 14008 14008 14008 14008 14008 14008 14008 14008 14008 14008 14008 14008 14008 14008 14008 14008 14008 14008
				14008 14008 14008 14008 14008 14008 14008 14008 14008 14008 14008 14008 14008 14008 14008 14008 14008 14008 14008 14008 14008 14008 14008 14008 14008 14008 14008 14008 14008 14008 14008 14008
				14008 14008 14008 14008 14008 14008 14008 14008 14008 14008 14008 14008 14008 14008 14008 14008 14008 14008 14008 14008 14008 14008 14008 14008 14008 14008 14008 14008 14008 14008 14008 14008
				14008 14008 14008 14008 14008 14008 14008 14008 14008 14008 14008 14008 14008 14008 14008 14008 14008 14008 14008 14008 14008 14008 14008 14008 14008 14008 14008 14008 14008 14008 14008 14008
				14008 14008 14008 14008 14008 14008 14008 14008 14008 14008 14008 14008 14008 14008 14008 14008 14008 14008 14008 14008 14008 14008 14008 14008 14008 14008 14008 14008 14008 14008 14008 14008
				14008 14008 14008 14008 14008 14008 14008 14008 14008 14008 14008 14008 14008 14008 14008 14008 14008 14008 14008 14008 14008 14008 14008 14008 14008 14008 14008 14008 14008 14008 14008 14008
				14008 14008 14008 14008 14008 14008 14008 14008 14008 14008 14008 14008 14008 14008 14008 14008 14008 14008 14008 14008 14008 14008 14008 14008 14008 14008 14008 14008 14008 14008 14008 14008
				14008 14008 14008 14008 14008 14008 14008 14008 14008 14008 14008 14008 14008 14008 14008 14008 14008 14008 14008 14008 14008 14008 14008 14008 14008 14008 14008 14008 14008 14008 14008 14008
				14008 14008 14008 14008 14008 14008 14008 14008 14008 14008 14008 14008 14008 14008 14008 14008 14008 14008 14008 14008 14008 14008 14008 14008 14008 14008 14008 14008 14008 14008 14008 14008
				14008 14008 14008 14008 14008 14008 14008 14008 14008 14008 14008 14008 14008 14008 14008 14008 14008 14008 14008 14008 14008 14008 14008 14008 14008 14008 14008 14008 14008 14008 14008 14008
				14008 14008 14008 14008 14008 14008 14008 14008 14008 14008 14008 14008 14008 14008 14008 14008 14008 14008 14008 14008 14008 14008 14008 14008 14008 14008 14008 14008 14008 14008 14008 14008
				14008 14008 14008 14008 14008 14008 14008 14008 14008 14008 14008 14008 14008 14008 14008 14008 14008 14008 14008 14008 14008 14008 14008 14008 14008 14008 14008 14008 14008 14008 14008 14008
				14008 14008 14008 14008 14008 14008 14008 14008 14008 14008 14008 14008 14008 14008 14008 14008 14008 14008 14008 14008 14008 14008 14008 14008 14008 14008 14008 14008 14008 14008 14008 14008
				14008 14008 14008 14008 14008 14008 14008 14008 14008 14008 14008 14008 14008 14008 14008 14008 14008 14008 14008 14008 14008 14008 14008 14008 14008 14008 14008 14008 14008 14008 14008 14008
				14008 14008 14008 14008 14008 14008 14008 14008 14008 14008 14008 14008 14008 14008 14008 14008 14008 14008 14008 14008 14008 14008 14008 14008 14008 14008 14008 14008 14008 14008 14008 14008
				14008 14008 14008 14008 14008 14008 14008 14008 14008 14008 14008 14008 14008 14008 14008 14008 14008 14008 14008 14008 14008 14008 14008 14008 14008 14008 14008 14008 14008 14008 14008 14008
				14008 14008 14008 14008 14008 14008 14008 14008 14008 14008 14008 14008 14008 14008 14008 14008 14008 14008 14008 14008 14008 14008 14008 14008 14008 14008 14008 14008 14008 14008 14008 14008
				14008 14008 14008 14008 14008 14008 14008 14008 14008 14008 14008 14008 14008 14008 14008 14008 14008 14008 14008 14008 14008 14008 14008 14008 14008 14008 14008 14008 14008 14008 14008 14008
				14008 14008 14008 14008 14008 14008 14008 14008 14008 14008 14008 14008 14008 14008 14008 14008 14008 14008 14008 14008 14008 14008 14008 14008 14008 14008 14008 14008 14008 14008 14008 14008
				14008 14008 14008 14008 14008 14008 14008 14008 14008 14008 14008 14008 14008 14008 14008 14008 14008 14008 14008 14008 14008 14008 14008 14008 14008 14008 14008 14008 14008 14008 14008 14008
				14008 14008 14008 14008 14008 14008 14008 14008 14008 14008 14008 14008 14008 14008 14008 14008 14008 14008 14008 14008 14008 14008 14008 14008 14008 14008 14008 14008 14008 14008 14008 14008
				14008 14008 14008 14008 14008 14008 14008 14008 14008 14008 14008 14008 14008 14008 14008 14008 14008 14008 14008 14008 14008 14008 14008 14008 14008 14008 14008 14008 14008 14008 14008 14008
				14008 14008 14008 14008 14008 14008 14008 14008 14008 14008 14008 14008 14008 14008 14008 14008 14008 14008 14008 14008 14008 14008 14008 14008 14008 14008 14008 14008 14008 14008 14008 14008
				14008 14008 14008 14008 14008 14008 14008 14008 14008 14008 14008 14008 14008 14008 14008 14008 14008 14008 14008 14008 14008 14008 14008 14008 14008 14008 14008 14008 14008 14008 14008 14008
				14008 14008 14008 14008 14008 14008 14008 14008 14008 14008 14008 14008 14008 14008 14008 14008 14008 14008 14008 14008 14008 14008 14008 14008 14008 14008 14008 14008 14008 14008 14008 14008
				14008 14008 14008 14008 14008 14008 14008 14008 14008 14008 14008 14008 14008 14008 14008 14008 14008 14008 14008 14008 14008 14008 14008 14008 14008 14008 14008 14008 14008 14008 14008 14008
				14008 14008 14008 14008 14008 14008 14008 14008 14008 14008 14008 14008 14008 14008 14008 14008 14008 14008 14008 14008 14008 14008 14008 14008 14008 14008 14008 14008 14008 14008 14008 14008
				14008 14008 14008 14008 14008 14008 14008 14008 14008 14008 14008 14008 14008 14008 14008 14008 14008 14008 14008 14008 14008 14008 14008 14008 14008 14008 14008 14008 14008 14008 14008 14008
				14008 14008 14008 14008 14008 14008 14008 14008 14008 14008 14008 14008 14008 14008 14008 14008 14008 14008 14008 14008 14008 14008 14008 14008 14008 14008 14008 14008 14008 14008 14008 14008
				14008 14008 14008 14008 14008 14008 14008 14008 14008 14008 14008 14008 14008 14008 14008 14008 14008 14008 14008 14008 14008 14008 14008 14008 14008 14008 14008 14008 14008 14008 14008 14008
				14008 14008 14008 14008 14008 14008 14008 14008 14008 14008 14008 14008 14008 14008 14008 14008 14008 14008 14008 14008 14008 14008 14008 14008 14008 14008 14008 14008 14008 14008 14008 14008
				14008 14008 14008 14008 14008 14008 14008 14008 14008 14008 14008 14008 14008 14008 14008 14008 14008 14008 14008 14008 14008 14008 14008 14008 14008 14008 14008 14008 14008 14008 14008 14008
				14008 14008 14008 14008 14008 14008 14008 14008 14008 14008 14008 14008 14008 14008 14008 14008 14008 14008 14008 14008 14008 14008 14008 14008 14008 14008 14008 14008 14008 14008 14008 14008
				14008 14008 14008 14008 14008 14008 14008 14008 14008 14008 14008 14008 14008 14008 14008 14008 14008 14008 14008 14008 14008 14008 14008 14008 14008 14008 14008 14008 14008 14008 14008 14008
				14008 14008 14008 14008 14008 14008 14008 14008 14008 14008 14008 14008 14008 14008 14008 14008 14008 14008 14008 14008 14008 14008 14008 14008 14008 14008 14008 14008 14008 14008 14008 14008
				14008 14008 14008 14008 14008 14008 14008 14008 14008 14008 14008 14008 14008 14008 14008 14008 14008 14008 14008 14008 14008 14008 14008 14008 14008 14008 14008 14008 14008 14008 14008 14008
				14008 14008 14008 14008 14008 14008 14008 14008 14008 14008 14008 14008 14008 14008 14008 14008 14008 14008 14008 14008 14008 14008 14008 14008 14008 14008 14008 14008 14008 14008 14008 14008
				14008 14008 14008 14008 14008 14008 14008 14008 14008 14008 14008 14008 14008 14008 14008 14008 14008 14008 14008 14008 14008 14008 14008 14008 14008 14008 14008 14008 14008 14008 14008 14008
				14008 14008 14008 14008 14008 14008 14008 14008 14008 14008 14008 14008 14008 14008 14008 14008 14008 14008 14008 14008 14008 14008 14008 14008 14008 14008 14008 14008 14008 14008 14008 14008
				14008 14008 14008 14008 14008 14008 14008 14008 14008 14008 14008 14008 14008 14008 14008 14008 14008 14008 14008 14008 14008 14008 14008 14008 14008 14008 14008 14008 14008 14008 14008 14008
				14008 14008 14008 14008 14008 14008 14008 14008 14008 14008 14008 14008 14008 14008 14008 14008 14008 14008 14008 14008 14008 14008 14008 14008 14008 14008 14008 14008 14008 14008 14008 14008
				14008 14008 14008 14008 14008 14008 14008 14008 14008 14008 14008 14008 14008 14008 14008 14008 14008 14008 14008 14008 14008 14008 14008 14008 14008 14008 14008 14008 14008 14008 14008 14008
				14008 14008 14008 14008 14008 14008 14008 14008 14008 14008 14008 14008 14008 14008 14008 14008 14008 14008 14008 14008 14008 14008 14008 14008 14008 14008 14008 14008 14008 14008 14008 14008
				14008 14008 14008>;

			PS_Config_Lmt_Short_Rawdata_N = <
				10100 10100 10100 10100 10100 10100 10100 10100 10100 10100 10100 10100 10100 10100 10100 10100 10100 10100 10100 10100 10100 10100 10100 10100 10100 10100 10100 10100 10100 10100 10100 10100
				10100 10100 10100 10100 10100 10100 10100 10100 10100 10100 10100 10100 10100 10100 10100 10100 10100 10100 10100 10100 10100 10100 10100 10100 10100 10100 10100 10100 10100 10100 10100 10100
				10100 10100 10100 10100 10100 10100 10100 10100 10100 10100 10100 10100 10100 10100 10100 10100 10100 10100 10100 10100 10100 10100 10100 10100 10100 10100 10100 10100 10100 10100 10100 10100
				10100 10100 10100 10100 10100 10100 10100 10100 10100 10100 10100 10100 10100 10100 10100 10100 10100 10100 10100 10100 10100 10100 10100 10100 10100 10100 10100 10100 10100 10100 10100 10100
				10100 10100 10100 10100 10100 10100 10100 10100 10100 10100 10100 10100 10100 10100 10100 10100 10100 10100 10100 10100 10100 10100 10100 10100 10100 10100 10100 10100 10100 10100 10100 10100
				10100 10100 10100 10100 10100 10100 10100 10100 10100 10100 10100 10100 10100 10100 10100 10100 10100 10100 10100 10100 10100 10100 10100 10100 10100 10100 10100 10100 10100 10100 10100 10100
				10100 10100 10100 10100 10100 10100 10100 10100 10100 10100 10100 10100 10100 10100 10100 10100 10100 10100 10100 10100 10100 10100 10100 10100 10100 10100 10100 10100 10100 10100 10100 10100
				10100 10100 10100 10100 10100 10100 10100 10100 10100 10100 10100 10100 10100 10100 10100 10100 10100 10100 10100 10100 10100 10100 10100 10100 10100 10100 10100 10100 10100 10100 10100 10100
				10100 10100 10100 10100 10100 10100 10100 10100 10100 10100 10100 10100 10100 10100 10100 10100 10100 10100 10100 10100 10100 10100 10100 10100 10100 10100 10100 10100 10100 10100 10100 10100
				10100 10100 10100 10100 10100 10100 10100 10100 10100 10100 10100 10100 10100 10100 10100 10100 10100 10100 10100 10100 10100 10100 10100 10100 10100 10100 10100 10100 10100 10100 10100 10100
				10100 10100 10100 10100 10100 10100 10100 10100 10100 10100 10100 10100 10100 10100 10100 10100 10100 10100 10100 10100 10100 10100 10100 10100 10100 10100 10100 10100 10100 10100 10100 10100
				10100 10100 10100 10100 10100 10100 10100 10100 10100 10100 10100 10100 10100 10100 10100 10100 10100 10100 10100 10100 10100 10100 10100 10100 10100 10100 10100 10100 10100 10100 10100 10100
				10100 10100 10100 10100 10100 10100 10100 10100 10100 10100 10100 10100 10100 10100 10100 10100 10100 10100 10100 10100 10100 10100 10100 10100 10100 10100 10100 10100 10100 10100 10100 10100
				10100 10100 10100 10100 10100 10100 10100 10100 10100 10100 10100 10100 10100 10100 10100 10100 10100 10100 10100 10100 10100 10100 10100 10100 10100 10100 10100 10100 10100 10100 10100 10100
				10100 10100 10100 10100 10100 10100 10100 10100 10100 10100 10100 10100 10100 10100 10100 10100 10100 10100 10100 10100 10100 10100 10100 10100 10100 10100 10100 10100 10100 10100 10100 10100
				10100 10100 10100 10100 10100 10100 10100 10100 10100 10100 10100 10100 10100 10100 10100 10100 10100 10100 10100 10100 10100 10100 10100 10100 10100 10100 10100 10100 10100 10100 10100 10100
				10100 10100 10100 10100 10100 10100 10100 10100 10100 10100 10100 10100 10100 10100 10100 10100 10100 10100 10100 10100 10100 10100 10100 10100 10100 10100 10100 10100 10100 10100 10100 10100
				10100 10100 10100 10100 10100 10100 10100 10100 10100 10100 10100 10100 10100 10100 10100 10100 10100 10100 10100 10100 10100 10100 10100 10100 10100 10100 10100 10100 10100 10100 10100 10100
				10100 10100 10100 10100 10100 10100 10100 10100 10100 10100 10100 10100 10100 10100 10100 10100 10100 10100 10100 10100 10100 10100 10100 10100 10100 10100 10100 10100 10100 10100 10100 10100
				10100 10100 10100 10100 10100 10100 10100 10100 10100 10100 10100 10100 10100 10100 10100 10100 10100 10100 10100 10100 10100 10100 10100 10100 10100 10100 10100 10100 10100 10100 10100 10100
				10100 10100 10100 10100 10100 10100 10100 10100 10100 10100 10100 10100 10100 10100 10100 10100 10100 10100 10100 10100 10100 10100 10100 10100 10100 10100 10100 10100 10100 10100 10100 10100
				10100 10100 10100 10100 10100 10100 10100 10100 10100 10100 10100 10100 10100 10100 10100 10100 10100 10100 10100 10100 10100 10100 10100 10100 10100 10100 10100 10100 10100 10100 10100 10100
				10100 10100 10100 10100 10100 10100 10100 10100 10100 10100 10100 10100 10100 10100 10100 10100 10100 10100 10100 10100 10100 10100 10100 10100 10100 10100 10100 10100 10100 10100 10100 10100
				10100 10100 10100 10100 10100 10100 10100 10100 10100 10100 10100 10100 10100 10100 10100 10100 10100 10100 10100 10100 10100 10100 10100 10100 10100 10100 10100 10100 10100 10100 10100 10100
				10100 10100 10100 10100 10100 10100 10100 10100 10100 10100 10100 10100 10100 10100 10100 10100 10100 10100 10100 10100 10100 10100 10100 10100 10100 10100 10100 10100 10100 10100 10100 10100
				10100 10100 10100 10100 10100 10100 10100 10100 10100 10100 10100 10100 10100 10100 10100 10100 10100 10100 10100 10100 10100 10100 10100 10100 10100 10100 10100 10100 10100 10100 10100 10100
				10100 10100 10100 10100 10100 10100 10100 10100 10100 10100 10100 10100 10100 10100 10100 10100 10100 10100 10100 10100 10100 10100 10100 10100 10100 10100 10100 10100 10100 10100 10100 10100
				10100 10100 10100 10100 10100 10100 10100 10100 10100 10100 10100 10100 10100 10100 10100 10100 10100 10100 10100 10100 10100 10100 10100 10100 10100 10100 10100 10100 10100 10100 10100 10100
				10100 10100 10100 10100 10100 10100 10100 10100 10100 10100 10100 10100 10100 10100 10100 10100 10100 10100 10100 10100 10100 10100 10100 10100 10100 10100 10100 10100 10100 10100 10100 10100
				10100 10100 10100 10100 10100 10100 10100 10100 10100 10100 10100 10100 10100 10100 10100 10100 10100 10100 10100 10100 10100 10100 10100 10100 10100 10100 10100 10100 10100 10100 10100 10100
				10100 10100 10100 10100 10100 10100 10100 10100 10100 10100 10100 10100 10100 10100 10100 10100 10100 10100 10100 10100 10100 10100 10100 10100 10100 10100 10100 10100 10100 10100 10100 10100
				10100 10100 10100 10100 10100 10100 10100 10100 10100 10100 10100 10100 10100 10100 10100 10100 10100 10100 10100 10100 10100 10100 10100 10100 10100 10100 10100 10100 10100 10100 10100 10100
				10100 10100 10100 10100 10100 10100 10100 10100 10100 10100 10100 10100 10100 10100 10100 10100 10100 10100 10100 10100 10100 10100 10100 10100 10100 10100 10100 10100 10100 10100 10100 10100
				10100 10100 10100 10100 10100 10100 10100 10100 10100 10100 10100 10100 10100 10100 10100 10100 10100 10100 10100 10100 10100 10100 10100 10100 10100 10100 10100 10100 10100 10100 10100 10100
				10100 10100 10100 10100 10100 10100 10100 10100 10100 10100 10100 10100 10100 10100 10100 10100 10100 10100 10100 10100 10100 10100 10100 10100 10100 10100 10100 10100 10100 10100 10100 10100
				10100 10100 10100 10100 10100 10100 10100 10100 10100 10100 10100 10100 10100 10100 10100 10100 10100 10100 10100 10100 10100 10100 10100 10100 10100 10100 10100 10100 10100 10100 10100 10100
				10100 10100 10100 10100 10100 10100 10100 10100 10100 10100 10100 10100 10100 10100 10100 10100 10100 10100 10100 10100 10100 10100 10100 10100 10100 10100 10100 10100 10100 10100 10100 10100
				10100 10100 10100 10100 10100 10100 10100 10100 10100 10100 10100 10100 10100 10100 10100 10100 10100 10100 10100 10100 10100 10100 10100 10100 10100 10100 10100 10100 10100 10100 10100 10100
				10100 10100 10100 10100 10100 10100 10100 10100 10100 10100 10100 10100 10100 10100 10100 10100 10100 10100 10100 10100 10100 10100 10100 10100 10100 10100 10100 10100 10100 10100 10100 10100
				10100 10100 10100 10100 10100 10100 10100 10100 10100 10100 10100 10100 10100 10100 10100 10100 10100 10100 10100 10100 10100 10100 10100 10100 10100 10100 10100 10100 10100 10100 10100 10100
				10100 10100 10100 10100 10100 10100 10100 10100 10100 10100 10100 10100 10100 10100 10100 10100 10100 10100 10100 10100 10100 10100 10100 10100 10100 10100 10100 10100 10100 10100 10100 10100
				10100 10100 10100 10100 10100 10100 10100 10100 10100 10100 10100 10100 10100 10100 10100 10100 10100 10100 10100 10100 10100 10100 10100 10100 10100 10100 10100 10100 10100 10100 10100 10100
				10100 10100 10100 10100 10100 10100 10100 10100 10100 10100 10100 10100 10100 10100 10100 10100 10100 10100 10100 10100 10100 10100 10100 10100 10100 10100 10100 10100 10100 10100 10100 10100
				10100 10100 10100 10100 10100 10100 10100 10100 10100 10100 10100 10100 10100 10100 10100 10100 10100 10100 10100 10100 10100 10100 10100 10100 10100 10100 10100 10100 10100 10100 10100 10100
				10100 10100 10100 10100 10100 10100 10100 10100 10100 10100 10100 10100 10100 10100 10100 10100 10100 10100 10100 10100 10100 10100 10100 10100 10100 10100 10100 10100 10100 10100 10100 10100
				10100 10100 10100 10100 10100 10100 10100 10100 10100 10100 10100 10100 10100 10100 10100 10100 10100 10100 10100 10100 10100 10100 10100 10100 10100 10100 10100 10100 10100 10100 10100 10100
				10100 10100 10100 10100 10100 10100 10100 10100 10100 10100 10100 10100 10100 10100 10100 10100 10100 10100 10100 10100 10100 10100 10100 10100 10100 10100 10100 10100 10100 10100 10100 10100
				10100 10100 10100 10100 10100 10100 10100 10100 10100 10100 10100 10100 10100 10100 10100 10100 10100 10100 10100 10100 10100 10100 10100 10100 10100 10100 10100 10100 10100 10100 10100 10100
				10100 10100 10100>;

			PS_Config_Lmt_Open_Rawdata_P = <
				3596 3542 3563 3528 3619 3574 3487 3418 3203 3355 3372 3361 3344 3428 3542 3624 3491 3449 3448 3425 3511 3497 3402 3336 3130 3263 3262 3264 3274 3381 3465 3565
				3570 3558 3547 3595 3516 3458 3417 3344 3140 3264 3250 3312 3362 3430 3477 3512 3488 3458 3451 3487 3423 3376 3343 3278 3061 3178 3189 3250 3298 3371 3410 3459
				3656 3586 3477 3546 3542 3584 3532 3451 3193 3330 3402 3425 3420 3413 3504 3595 3547 3483 3399 3434 3446 3481 3458 3364 3113 3263 3311 3319 3323 3341 3458 3554
				3591 3565 3502 3533 3613 3486 3418 3385 3192 3273 3319 3312 3382 3437 3525 3537 3488 3494 3417 3449 3521 3400 3348 3315 3113 3189 3225 3248 3312 3365 3465 3495
				3707 3659 3533 3432 3563 3519 3550 3509 3175 3322 3383 3465 3493 3495 3494 3561 3588 3549 3439 3361 3458 3425 3449 3432 3108 3248 3318 3375 3386 3400 3424 3547
				3617 3589 3505 3460 3558 3596 3456 3396 3249 3304 3311 3367 3364 3456 3516 3570 3493 3491 3442 3375 3479 3504 3374 3326 3169 3235 3229 3274 3299 3385 3451 3543
				3610 3697 3600 3484 3400 3549 3487 3526 3238 3292 3367 3437 3526 3574 3581 3551 3479 3589 3505 3403 3336 3452 3406 3431 3165 3231 3288 3365 3425 3462 3481 3509
				3736 3620 3536 3469 3432 3546 3564 3430 3242 3379 3360 3374 3437 3452 3537 3567 3605 3491 3444 3406 3347 3466 3474 3347 3137 3306 3291 3295 3343 3388 3472 3535
				3634 3655 3679 3599 3490 3406 3554 3495 3368 3399 3376 3460 3537 3638 3690 3663 3567 3519 3577 3507 3409 3343 3458 3413 3301 3329 3312 3382 3463 3535 3585 3593
				3743 3788 3605 3529 3469 3435 3554 3574 3290 3407 3472 3459 3480 3551 3572 3621 3624 3659 3487 3444 3416 3358 3483 3486 3221 3302 3390 3383 3393 3448 3505 3584
				3668 3654 3600 3640 3567 3463 3379 3536 3371 3505 3455 3439 3529 3619 3739 3718 3556 3591 3474 3542 3477 3382 3325 3438 3294 3441 3388 3376 3449 3544 3640 3649
				3680 3756 3736 3563 3502 3445 3402 3532 3336 3420 3455 3528 3522 3556 3637 3595 3616 3640 3610 3448 3417 3392 3334 3456 3213 3353 3353 3449 3449 3469 3537 3561
				3696 3693 3595 3560 3600 3533 3425 3302 3369 3505 3560 3516 3507 3613 3708 3766 3607 3589 3546 3448 3515 3455 3360 3248 3283 3424 3490 3445 3438 3528 3631 3691
				3700 3715 3708 3696 3533 3479 3413 3337 3381 3467 3469 3515 3591 3606 3642 3668 3582 3649 3600 3575 3420 3395 3367 3260 3295 3346 3404 3414 3514 3532 3558 3605
				3743 3726 3637 3556 3529 3578 3505 3360 3341 3497 3553 3617 3577 3588 3701 3736 3652 3638 3539 3511 3420 3495 3437 3283 3263 3410 3473 3550 3507 3518 3619 3698
				3700 3736 3654 3665 3669 3507 3449 3344 3451 3525 3529 3540 3595 3673 3698 3669 3621 3621 3600 3565 3553 3403 3379 3298 3383 3432 3403 3469 3486 3589 3620 3613
				3808 3787 3672 3605 3532 3501 3543 3441 3462 3483 3560 3623 3694 3658 3679 3714 3703 3696 3588 3509 3490 3393 3469 3362 3360 3404 3473 3547 3627 3589 3607 3672
				3719 3747 3680 3612 3633 3638 3476 3375 3382 3582 3570 3585 3602 3661 3761 3705 3633 3663 3572 3560 3536 3525 3379 3298 3344 3512 3483 3460 3532 3551 3679 3663
				3833 3845 3728 3628 3571 3501 3472 3470 3502 3599 3537 3620 3693 3778 3740 3686 3736 3746 3647 3553 3486 3470 3382 3395 3427 3488 3453 3530 3606 3708 3670 3645
				3750 3768 3696 3640 3591 3614 3616 3407 3445 3516 3634 3630 3651 3682 3738 3759 3659 3675 3617 3533 3539 3518 3511 3306 3357 3473 3570 3544 3526 3612 3638 3717
				3740 3893 3801 3687 3599 3550 3480 3402 3537 3638 3645 3592 3683 3770 3824 3736 3658 3792 3703 3609 3529 3463 3456 3309 3444 3556 3542 3511 3592 3689 3757 3704
				3845 3809 3711 3654 3610 3567 3592 3543 3460 3591 3577 3703 3708 3732 3740 3747 3768 3721 3628 3582 3511 3522 3505 3432 3395 3488 3533 3634 3616 3602 3669 3679
				3777 3809 3843 3761 3663 3578 3528 3410 3589 3682 3696 3711 3666 3761 3823 3833 3672 3724 3742 3662 3585 3508 3449 3378 3540 3584 3620 3607 3584 3672 3747 3808
				3747 3913 3753 3679 3626 3588 3533 3507 3500 3592 3638 3634 3764 3785 3778 3729 3670 3831 3669 3598 3557 3488 3495 3411 3428 3518 3542 3586 3693 3694 3651 3698
				3817 3826 3757 3798 3722 3628 3544 3442 3553 3724 3732 3756 3778 3749 3805 3819 3729 3729 3689 3705 3634 3560 3488 3365 3470 3662 3638 3676 3669 3659 3714 3778
				3784 3801 3868 3712 3645 3596 3561 3460 3557 3633 3641 3696 3697 3844 3815 3773 3661 3721 3791 3630 3567 3530 3466 3414 3451 3554 3578 3596 3652 3773 3729 3683
				3879 3885 3810 3715 3770 3701 3607 3472 3551 3683 3771 3787 3816 3848 3774 3795 3791 3798 3718 3644 3679 3614 3544 3406 3441 3596 3715 3691 3736 3743 3687 3742
				3785 3848 3775 3822 3682 3620 3574 3483 3610 3693 3687 3697 3761 3770 3878 3822 3718 3735 3704 3752 3609 3549 3523 3386 3543 3574 3605 3626 3658 3715 3806 3767
				3920 3950 3868 3771 3690 3752 3680 3535 3565 3689 3745 3834 3855 3883 3875 3780 3803 3861 3784 3677 3621 3661 3602 3463 3479 3572 3661 3781 3763 3805 3775 3735
				3805 3850 3830 3745 3795 3648 3588 3487 3693 3746 3750 3747 3763 3823 3796 3866 3719 3784 3724 3676 3726 3574 3525 3425 3575 3673 3635 3668 3696 3722 3750 3840
				3812 3978 3931 3823 3732 3654 3718 3591 3686 3696 3743 3803 3903 3920 3911 3871 3711 3872 3852 3747 3647 3598 3642 3511 3574 3600 3628 3717 3844 3824 3836 3806
				3936 3865 3841 3789 3710 3764 3633 3515 3585 3824 3801 3809 3810 3816 3852 3792 3816 3780 3781 3683 3642 3696 3563 3446 3509 3705 3731 3693 3732 3753 3760 3788
				3829 3871 3976 3887 3794 3708 3638 3641 3705 3819 3749 3798 3864 3950 3936 3900 3750 3771 3876 3810 3722 3624 3584 3556 3610 3698 3656 3684 3778 3894 3851 3873
				3868 3992 3857 3795 3759 3684 3740 3551 3613 3719 3889 3865 3879 3859 3844 3857 3788 3880 3785 3742 3661 3627 3686 3486 3533 3637 3767 3788 3757 3778 3781 3799
				3854 3901 3878 3934 3859 3773 3693 3560 3626 3844 3878 3809 3868 3908 3978 3936 3782 3822 3784 3838 3789 3700 3613 3504 3533 3743 3766 3717 3754 3827 3932 3897
				3865 3939 3997 3815 3766 3732 3663 3652 3526 3747 3771 3938 3927 3920 3886 3834 3788 3858 3890 3742 3717 3640 3609 3599 3448 3661 3696 3822 3852 3796 3808 3816
				3932 3907 3890 3841 3901 3830 3745 3606 3687 3683 3903 3936 3873 3907 3938 3976 3862 3841 3823 3752 3813 3767 3689 3533 3570 3582 3799 3819 3778 3788 3859 3964
				3859 3927 3941 3963 3782 3738 3712 3577 3568 3586 3796 3829 4011 3959 3942 3879 3796 3850 3871 3857 3715 3693 3623 3528 3486 3502 3718 3752 3896 3887 3823 3844
				3956 3985 3907 3855 3805 3868 3803 3656 3658 3746 3736 3956 3995 3899 3928 3929 3875 3918 3848 3789 3721 3785 3749 3602 3567 3624 3638 3855 3882 3806 3815 3903
				3879 3914 3924 3896 3922 3746 3722 3621 3596 3630 3642 3857 3883 4030 3988 3939 3823 3857 3859 3831 3827 3690 3689 3539 3514 3537 3553 3771 3806 3913 3915 3855
				3969 3969 3934 3829 3782 3733 3799 3670 3581 3658 3745 3732 3956 3963 3873 3875 3899 3892 3875 3771 3719 3652 3725 3626 3511 3570 3628 3638 3861 3854 3789 3815
				3843 3892 3862 3845 3816 3844 3680 3578 3589 3593 3628 3635 3851 3848 4001 3927 3780 3840 3808 3782 3761 3754 3627 3554 3512 3514 3539 3550 3773 3774 3890 3903
				3976 4015 3953 3903 3787 3746 3707 3697 3578 3633 3712 3792 3787 3973 3981 3868 3882 3953 3886 3855 3738 3693 3635 3640 3488 3554 3620 3670 3686 3878 3876 3819
				3868 3894 3886 3840 3809 3784 3817 3588 3585 3640 3648 3673 3686 3866 3872 4001 3799 3831 3840 3788 3750 3729 3732 3543 3519 3564 3564 3586 3602 3792 3808 3936
				3866 4027 4005 3928 3859 3749 3719 3613 3652 3627 3683 3754 3838 3879 3994 3971 3796 3928 3949 3865 3819 3704 3668 3549 3539 3537 3607 3666 3719 3781 3908 3920
				3967 3917 3880 3857 3798 3770 3752 3722 3598 3637 3693 3693 3729 3773 3890 3864 3875 3850 3831 3817 3756 3717 3707 3654 3516 3564 3613 3606 3630 3680 3816 3843
				3883 3922 4020 3984 3892 3829 3726 3633 3698 3701 3677 3724 3799 3921 3920 3976 3809 3844 3927 3932 3834 3788 3684 3582 3589 3588 3588 3648 3717 3806 3829 3946
				3889 4032 3914 3868 3830 3777 3756 3675 3600 3648 3680 3732 3742 3815 3827 3880 3838 3932 3854 3822 3791 3736 3708 3627 3518 3567 3607 3654 3661 3718 3745 3862
				5120 5120 5120>;

			PS_Config_Lmt_Open_Rawdata_N = <
				1541 1518 1527 1512 1551 1531 1494 1465 1372 1438 1445 1440 1433 1469 1518 1553 1496 1478 1477 1468 1504 1498 1458 1429 1341 1398 1398 1399 1403 1449 1485 1528
				1530 1525 1520 1540 1507 1482 1464 1433 1345 1399 1393 1419 1441 1470 1490 1505 1495 1482 1479 1494 1467 1447 1432 1405 1312 1362 1366 1393 1413 1444 1461 1482
				1567 1537 1490 1519 1518 1536 1513 1479 1368 1427 1458 1468 1465 1462 1501 1540 1520 1492 1456 1471 1477 1492 1482 1441 1334 1398 1419 1422 1424 1432 1482 1523
				1539 1528 1501 1514 1548 1494 1465 1450 1368 1402 1422 1419 1449 1473 1510 1516 1495 1497 1464 1478 1509 1457 1435 1420 1334 1366 1382 1392 1419 1442 1485 1498
				1588 1568 1514 1471 1527 1508 1521 1504 1360 1423 1450 1485 1497 1498 1497 1526 1537 1521 1474 1440 1482 1468 1478 1471 1332 1392 1422 1446 1451 1457 1467 1520
				1550 1538 1502 1483 1525 1541 1481 1455 1392 1416 1419 1443 1441 1481 1507 1530 1497 1496 1475 1446 1491 1501 1446 1425 1358 1386 1384 1403 1414 1450 1479 1518
				1547 1584 1543 1493 1457 1521 1494 1511 1387 1411 1443 1473 1511 1531 1534 1522 1491 1538 1502 1458 1429 1479 1459 1470 1356 1384 1409 1442 1468 1483 1492 1504
				1601 1551 1515 1486 1471 1519 1527 1470 1389 1448 1440 1446 1473 1479 1516 1528 1545 1496 1476 1459 1434 1485 1489 1434 1344 1417 1410 1412 1432 1452 1488 1515
				1557 1566 1576 1542 1495 1459 1523 1498 1443 1456 1447 1483 1516 1559 1581 1570 1528 1508 1533 1503 1461 1432 1482 1462 1414 1426 1419 1449 1484 1515 1536 1540
				1604 1623 1545 1512 1486 1472 1523 1531 1410 1460 1488 1482 1491 1522 1531 1552 1553 1568 1494 1476 1464 1439 1492 1494 1380 1415 1453 1450 1454 1477 1502 1536
				1572 1566 1543 1560 1528 1484 1448 1515 1444 1502 1480 1474 1512 1551 1602 1593 1524 1539 1489 1518 1490 1449 1425 1473 1411 1474 1452 1447 1478 1519 1560 1564
				1577 1609 1601 1527 1501 1476 1458 1513 1429 1465 1480 1512 1509 1524 1558 1540 1549 1560 1547 1477 1464 1453 1429 1481 1377 1437 1437 1478 1478 1486 1516 1526
				1584 1582 1540 1525 1543 1514 1468 1415 1444 1502 1525 1507 1503 1548 1589 1614 1546 1538 1519 1477 1506 1480 1440 1392 1407 1467 1495 1476 1473 1512 1556 1582
				1585 1592 1589 1584 1514 1491 1462 1430 1449 1486 1486 1506 1539 1545 1561 1572 1535 1564 1543 1532 1465 1455 1443 1397 1412 1434 1459 1463 1506 1513 1525 1545
				1604 1597 1558 1524 1512 1533 1502 1440 1432 1498 1522 1550 1533 1537 1586 1601 1565 1559 1516 1504 1465 1498 1473 1407 1398 1461 1488 1521 1503 1507 1551 1585
				1585 1601 1566 1570 1572 1503 1478 1433 1479 1510 1512 1517 1540 1574 1585 1572 1552 1552 1543 1528 1522 1458 1448 1413 1450 1471 1458 1486 1494 1538 1551 1548
				1632 1623 1573 1545 1513 1500 1518 1474 1483 1492 1525 1552 1583 1567 1576 1591 1587 1584 1537 1504 1495 1454 1486 1441 1440 1459 1488 1520 1554 1538 1546 1573
				1594 1606 1577 1548 1557 1559 1489 1446 1449 1535 1530 1536 1543 1569 1612 1588 1557 1570 1531 1525 1515 1510 1448 1413 1433 1505 1492 1483 1513 1522 1576 1570
				1642 1648 1597 1555 1530 1500 1488 1487 1501 1542 1516 1551 1582 1619 1603 1579 1601 1605 1563 1522 1494 1487 1449 1455 1468 1495 1480 1513 1545 1589 1573 1562
				1607 1615 1584 1560 1539 1549 1549 1460 1476 1507 1557 1555 1564 1578 1602 1611 1568 1575 1550 1514 1516 1507 1504 1417 1438 1488 1530 1519 1511 1548 1559 1593
				1603 1668 1629 1580 1542 1521 1491 1458 1516 1559 1562 1539 1578 1615 1639 1601 1567 1625 1587 1546 1512 1484 1481 1418 1476 1524 1518 1504 1539 1581 1610 1587
				1648 1632 1590 1566 1547 1528 1539 1518 1483 1539 1533 1587 1589 1599 1603 1606 1615 1594 1555 1535 1504 1509 1502 1471 1455 1495 1514 1557 1549 1543 1572 1576
				1618 1632 1647 1612 1570 1533 1512 1461 1538 1578 1584 1590 1571 1612 1638 1642 1573 1596 1603 1569 1536 1503 1478 1447 1517 1536 1551 1546 1536 1573 1606 1632
				1606 1677 1608 1576 1554 1537 1514 1503 1500 1539 1559 1557 1613 1622 1619 1598 1573 1642 1572 1542 1524 1495 1498 1462 1469 1507 1518 1537 1582 1583 1564 1585
				1636 1639 1610 1627 1595 1555 1519 1475 1522 1596 1599 1609 1619 1606 1630 1636 1598 1598 1581 1588 1557 1525 1495 1442 1487 1569 1559 1575 1572 1568 1591 1619
				1621 1629 1657 1591 1562 1541 1526 1483 1524 1557 1560 1584 1584 1647 1635 1617 1569 1594 1624 1555 1528 1513 1485 1463 1479 1523 1533 1541 1565 1617 1598 1578
				1662 1665 1633 1592 1615 1586 1546 1488 1522 1578 1616 1623 1635 1649 1617 1626 1624 1627 1593 1561 1576 1549 1519 1459 1474 1541 1592 1582 1601 1604 1580 1603
				1622 1649 1618 1638 1578 1551 1531 1492 1547 1582 1580 1584 1612 1615 1662 1638 1593 1600 1587 1608 1546 1521 1510 1451 1518 1531 1545 1554 1567 1592 1631 1614
				1680 1693 1657 1616 1581 1608 1577 1515 1528 1581 1605 1643 1652 1664 1660 1620 1630 1654 1621 1576 1552 1569 1543 1484 1491 1531 1569 1620 1612 1630 1618 1600
				1630 1650 1641 1605 1626 1563 1537 1494 1582 1605 1607 1606 1612 1638 1627 1657 1594 1621 1596 1575 1597 1531 1510 1468 1532 1574 1558 1572 1584 1595 1607 1645
				1633 1705 1684 1638 1599 1566 1593 1539 1579 1584 1604 1630 1672 1680 1676 1659 1590 1659 1651 1606 1563 1542 1561 1504 1531 1543 1555 1593 1647 1639 1644 1631
				1687 1656 1646 1624 1590 1613 1557 1506 1536 1639 1629 1632 1633 1635 1651 1625 1635 1620 1620 1578 1561 1584 1527 1477 1504 1588 1599 1582 1599 1608 1611 1623
				1641 1659 1704 1666 1626 1589 1559 1560 1588 1636 1606 1627 1656 1693 1687 1671 1607 1616 1661 1633 1595 1553 1536 1524 1547 1585 1567 1579 1619 1669 1650 1660
				1657 1711 1653 1626 1611 1579 1603 1522 1548 1594 1666 1656 1662 1654 1647 1653 1623 1663 1622 1603 1569 1554 1579 1494 1514 1558 1614 1623 1610 1619 1620 1628
				1651 1672 1662 1686 1654 1617 1582 1525 1554 1647 1662 1632 1657 1675 1705 1687 1621 1638 1621 1645 1624 1585 1548 1501 1514 1604 1614 1593 1609 1640 1685 1670
				1656 1688 1713 1635 1614 1599 1570 1565 1511 1606 1616 1687 1683 1680 1665 1643 1623 1653 1667 1603 1593 1560 1546 1542 1477 1569 1584 1638 1651 1627 1632 1635
				1685 1674 1667 1646 1672 1641 1605 1545 1580 1578 1672 1687 1660 1674 1687 1704 1655 1646 1638 1608 1634 1614 1581 1514 1530 1535 1628 1636 1619 1623 1654 1699
				1654 1683 1689 1698 1621 1602 1591 1533 1529 1537 1627 1641 1719 1696 1689 1662 1627 1650 1659 1653 1592 1582 1552 1512 1494 1501 1593 1608 1669 1666 1638 1647
				1695 1708 1674 1652 1630 1657 1630 1567 1567 1605 1601 1695 1712 1671 1683 1684 1660 1679 1649 1624 1594 1622 1606 1543 1528 1553 1559 1652 1663 1631 1635 1672
				1662 1677 1681 1669 1681 1605 1595 1552 1541 1555 1561 1653 1664 1727 1709 1688 1638 1653 1654 1642 1640 1581 1581 1516 1506 1516 1522 1616 1631 1677 1678 1652
				1701 1701 1686 1641 1621 1600 1628 1573 1534 1567 1605 1599 1695 1698 1660 1660 1671 1668 1660 1616 1594 1565 1596 1554 1504 1530 1555 1559 1654 1651 1624 1635
				1647 1668 1655 1648 1635 1647 1577 1533 1538 1540 1555 1558 1650 1649 1714 1683 1620 1645 1632 1621 1612 1609 1554 1523 1505 1506 1516 1521 1617 1617 1667 1672
				1704 1720 1694 1672 1623 1605 1588 1584 1533 1557 1591 1625 1623 1702 1706 1657 1663 1694 1665 1652 1602 1582 1558 1560 1495 1523 1551 1573 1579 1662 1661 1636
				1657 1669 1665 1645 1632 1621 1636 1537 1536 1560 1563 1574 1579 1657 1659 1714 1628 1642 1645 1623 1607 1598 1599 1518 1508 1527 1527 1537 1543 1625 1632 1687
				1657 1726 1716 1683 1654 1606 1594 1548 1565 1554 1578 1609 1645 1662 1711 1702 1627 1683 1692 1656 1636 1587 1572 1521 1516 1516 1546 1571 1594 1620 1675 1680
				1700 1678 1663 1653 1627 1615 1608 1595 1542 1558 1582 1582 1598 1617 1667 1656 1660 1650 1642 1636 1609 1593 1588 1566 1507 1527 1548 1545 1555 1577 1635 1647
				1664 1681 1723 1707 1668 1641 1597 1557 1585 1586 1576 1596 1628 1680 1680 1704 1632 1647 1683 1685 1643 1623 1579 1535 1538 1537 1537 1563 1593 1631 1641 1691
				1666 1728 1677 1657 1641 1618 1609 1575 1543 1563 1577 1599 1603 1635 1640 1663 1645 1685 1651 1638 1624 1601 1589 1554 1507 1528 1546 1566 1569 1593 1605 1655
				(-511) (-511) (-511)>;

			PS_Config_Lmt_FW_Rawdata_P = <
				1110 1121 1120 1114 1115 1114 1111 1132 1128 1121 1121 1121 1121 1124 1115 1122 1110 1120 1132 1124 1114 1138 1113 1131 1121 1121 1117 1120 1122 1117 1131 1107
				1117 1121 1124 1115 1120 1118 1124 1121 1111 1120 1124 1120 1127 1110 1127 1121 1120 1124 1118 1117 1127 1122 1108 1115 1135 1128 1115 1117 1115 1115 1121 1122
				1118 1120 1118 1114 1118 1115 1129 1129 1131 1104 1113 1125 1121 1113 1122 1122 1127 1128 1118 1118 1127 1117 1108 1117 1122 1117 1117 1114 1111 1132 1128 1129
				1128 1120 1125 1110 1115 1114 1125 1129 1106 1111 1121 1125 1120 1124 1117 1128 1128 1120 1127 1125 1124 1125 1125 1115 1124 1115 1118 1121 1125 1120 1122 1136
				1127 1114 1118 1115 1121 1117 1118 1108 1118 1117 1113 1115 1128 1121 1114 1129 1131 1118 1128 1117 1129 1125 1117 1125 1117 1127 1114 1121 1113 1108 1127 1108
				1115 1118 1120 1124 1121 1115 1122 1132 1118 1114 1114 1122 1121 1121 1115 1128 1108 1128 1118 1121 1122 1120 1118 1121 1121 1124 1113 1107 1115 1132 1122 1118
				1117 1115 1110 1122 1117 1122 1121 1122 1124 1125 1115 1122 1127 1120 1124 1124 1101 1120 1117 1124 1120 1131 1111 1114 1117 1120 1125 1115 1125 1114 1113 1108
				1117 1125 1115 1120 1125 1121 1120 1120 1117 1118 1117 1124 1124 1118 1120 1120 1121 1121 1127 1115 1122 1122 1121 1120 1120 1117 1127 1114 1104 1114 1129 1117
				1103 1118 1115 1114 1120 1113 1124 1121 1125 1111 1134 1107 1132 1122 1110 1115 1118 1113 1118 1115 1122 1121 1134 1107 1118 1111 1115 1122 1115 1127 1113 1122
				1117 1127 1131 1115 1120 1127 1122 1124 1115 1118 1118 1122 1125 1115 1114 1122 1118 1114 1124 1128 1120 1131 1117 1124 1122 1120 1122 1122 1111 1108 1104 1113
				1124 1138 1115 1113 1125 1118 1113 1125 1120 1121 1114 1128 1113 1131 1121 1111 1118 1118 1118 1118 1113 1120 1120 1128 1124 1118 1113 1115 1121 1115 1125 1122
				1117 1122 1125 1134 1117 1122 1124 1125 1129 1117 1118 1122 1127 1129 1115 1117 1120 1118 1110 1132 1125 1117 1131 1117 1108 1127 1120 1120 1127 1108 1111 1124
				1121 1132 1134 1117 1113 1114 1118 1122 1132 1114 1120 1115 1108 1117 1129 1122 1110 1118 1122 1128 1113 1114 1121 1127 1117 1110 1120 1117 1117 1115 1121 1122
				1121 1117 1121 1125 1131 1114 1125 1122 1120 1121 1115 1120 1121 1131 1131 1115 1120 1118 1120 1106 1134 1128 1115 1127 1125 1118 1128 1118 1115 1122 1108 1122
				1122 1125 1131 1131 1114 1115 1114 1122 1113 1111 1118 1115 1111 1113 1122 1121 1120 1107 1118 1114 1128 1115 1113 1118 1127 1122 1113 1121 1115 1121 1120 1111
				1127 1114 1115 1121 1127 1129 1120 1122 1132 1118 1115 1117 1120 1125 1128 1129 1120 1120 1121 1118 1107 1131 1124 1117 1114 1118 1120 1120 1122 1113 1127 1121
				1122 1118 1127 1131 1131 1114 1117 1124 1117 1124 1108 1115 1115 1118 1113 1124 1122 1124 1110 1118 1117 1124 1114 1115 1122 1120 1122 1108 1122 1117 1117 1115
				1121 1128 1117 1115 1120 1122 1121 1117 1111 1113 1120 1114 1122 1122 1120 1129 1122 1115 1118 1118 1120 1106 1135 1129 1106 1127 1114 1124 1117 1117 1118 1114
				1124 1132 1118 1127 1131 1136 1120 1117 1115 1114 1122 1107 1108 1113 1120 1114 1115 1118 1125 1107 1115 1113 1117 1110 1131 1122 1121 1127 1114 1122 1117 1114
				1113 1120 1124 1115 1111 1122 1127 1125 1114 1122 1114 1121 1113 1125 1124 1121 1111 1118 1118 1124 1115 1118 1107 1129 1115 1113 1127 1110 1125 1117 1114 1118
				1131 1127 1129 1117 1124 1132 1134 1118 1122 1118 1115 1122 1107 1111 1113 1124 1118 1111 1120 1120 1107 1117 1120 1127 1117 1117 1122 1117 1127 1111 1122 1118
				1111 1131 1121 1122 1118 1113 1113 1127 1111 1120 1122 1113 1118 1110 1128 1124 1120 1113 1118 1120 1122 1117 1118 1104 1131 1106 1115 1129 1108 1122 1118 1115
				1125 1129 1128 1128 1117 1124 1134 1139 1127 1121 1121 1118 1121 1111 1113 1127 1120 1118 1111 1120 1120 1110 1120 1115 1110 1114 1117 1128 1114 1122 1113 1120
				1125 1134 1128 1121 1122 1113 1110 1118 1120 1110 1121 1125 1108 1117 1113 1124 1129 1124 1114 1117 1118 1121 1118 1113 1114 1118 1111 1120 1135 1111 1129 1121
				1115 1117 1132 1127 1129 1115 1127 1132 1125 1128 1121 1128 1115 1121 1114 1117 1122 1122 1120 1110 1122 1118 1114 1117 1121 1114 1113 1120 1111 1113 1122 1122
				1125 1120 1125 1124 1122 1124 1113 1111 1118 1128 1113 1127 1125 1104 1120 1113 1136 1115 1124 1114 1117 1117 1124 1122 1127 1110 1127 1107 1121 1136 1111 1114
				1115 1104 1118 1129 1129 1132 1121 1127 1117 1111 1128 1120 1129 1120 1120 1120 1131 1121 1118 1118 1108 1121 1118 1114 1121 1114 1114 1114 1118 1118 1114 1113
				1120 1124 1125 1108 1125 1118 1127 1114 1117 1125 1122 1113 1131 1124 1103 1120 1128 1135 1117 1125 1117 1115 1115 1120 1127 1127 1107 1120 1111 1120 1129 1114
				1121 1121 1107 1127 1128 1128 1132 1114 1127 1115 1110 1124 1118 1129 1120 1122 1120 1125 1124 1121 1117 1108 1120 1117 1121 1124 1111 1117 1113 1117 1120 1118
				1113 1111 1127 1122 1117 1125 1122 1124 1125 1107 1122 1118 1115 1132 1125 1107 1117 1128 1135 1114 1121 1122 1118 1115 1111 1114 1132 1111 1118 1111 1117 1122
				1121 1120 1118 1106 1117 1129 1128 1132 1118 1127 1115 1113 1115 1115 1128 1115 1120 1124 1127 1124 1121 1115 1113 1115 1124 1124 1125 1114 1117 1113 1117 1120
				1111 1113 1117 1125 1118 1118 1127 1121 1114 1124 1108 1124 1122 1118 1129 1127 1128 1117 1129 1135 1115 1122 1118 1118 1120 1122 1122 1131 1110 1125 1114 1124
				1125 1124 1113 1125 1108 1117 1125 1128 1125 1128 1125 1117 1113 1117 1120 1131 1121 1120 1120 1125 1121 1121 1115 1111 1107 1121 1122 1125 1114 1117 1107 1111
				1124 1125 1113 1120 1129 1115 1118 1132 1117 1114 1125 1110 1127 1115 1117 1129 1115 1131 1117 1131 1134 1113 1122 1118 1117 1124 1121 1118 1117 1111 1125 1122
				1121 1117 1125 1115 1125 1104 1120 1127 1110 1131 1124 1122 1118 1111 1120 1120 1111 1125 1118 1124 1127 1120 1121 1114 1121 1120 1122 1124 1127 1113 1114 1118
				1118 1121 1128 1122 1120 1127 1118 1128 1127 1127 1117 1125 1108 1122 1121 1122 1111 1114 1127 1114 1128 1134 1114 1114 1120 1120 1129 1128 1113 1127 1108 1106
				1120 1120 1117 1127 1117 1124 1107 1117 1125 1110 1128 1128 1124 1121 1114 1111 1117 1113 1127 1121 1124 1124 1125 1120 1129 1121 1114 1118 1122 1125 1111 1125
				1127 1125 1120 1128 1114 1118 1121 1114 1118 1129 1125 1114 1129 1110 1124 1111 1118 1110 1111 1131 1113 1127 1131 1111 1122 1118 1121 1127 1122 1113 1129 1114
				1136 1110 1120 1117 1127 1118 1118 1108 1127 1124 1115 1125 1128 1121 1120 1110 1113 1122 1114 1124 1121 1114 1127 1121 1128 1120 1120 1117 1122 1125 1122 1118
				1127 1121 1127 1121 1122 1107 1114 1122 1121 1117 1118 1127 1113 1128 1113 1127 1117 1120 1111 1113 1128 1111 1129 1131 1132 1128 1117 1118 1122 1118 1117 1115
				1132 1129 1108 1121 1117 1127 1115 1113 1122 1125 1124 1117 1132 1131 1128 1118 1108 1115 1124 1113 1120 1120 1124 1121 1114 1124 1122 1122 1114 1120 1127 1128
				1121 1120 1118 1127 1121 1120 1106 1114 1129 1129 1120 1121 1124 1114 1129 1113 1131 1111 1120 1108 1113 1125 1111 1127 1118 1134 1127 1115 1118 1118 1111 1113
				1113 1120 1129 1106 1114 1120 1128 1113 1128 1122 1127 1127 1118 1132 1129 1111 1125 1110 1113 1122 1111 1118 1121 1127 1114 1115 1122 1127 1121 1108 1120 1120
				1113 1118 1118 1118 1127 1120 1121 1104 1120 1129 1120 1120 1122 1124 1115 1124 1122 1129 1104 1114 1115 1114 1131 1114 1124 1122 1135 1125 1121 1117 1122 1125
				1128 1124 1115 1125 1108 1125 1117 1128 1124 1124 1122 1120 1122 1120 1124 1124 1118 1128 1100 1114 1127 1120 1117 1125 1120 1136 1113 1124 1127 1124 1104 1108
				1118 1118 1114 1122 1114 1121 1120 1125 1114 1113 1127 1128 1117 1122 1120 1118 1115 1125 1128 1103 1114 1128 1111 1128 1125 1125 1122 1131 1128 1120 1114 1120
				1118 1117 1118 1124 1121 1122 1121 1114 1117 1122 1114 1125 1127 1122 1118 1125 1113 1128 1122 1100 1118 1124 1118 1115 1117 1114 1136 1108 1118 1127 1121 1128
				1125 1121 1120 1118 1122 1118 1122 1115 1120 1113 1114 1121 1107 1117 1115 1118 1117 1114 1127 1118 1108 1118 1111 1117 1118 1129 1124 1113 1124 1114 1114 1110
				3840 3840 3840>;

			PS_Config_Lmt_FW_Rawdata_N = <
				475 480 480 477 478 477 476 485 483 480 480 480 480 481 478 481 475 480 485 481 477 487 477 484 480 480 478 480 481 478 484 474
				478 480 481 478 480 479 481 480 476 480 481 480 483 475 483 480 480 481 479 478 483 481 475 478 486 483 478 478 478 478 480 481
				479 480 479 477 479 478 484 484 484 473 477 482 480 477 481 481 483 483 479 479 483 478 475 478 481 478 478 477 476 485 483 484
				483 480 482 475 478 477 482 484 474 476 480 482 480 481 478 483 483 480 483 482 481 482 482 478 481 478 479 480 482 480 481 487
				483 477 479 478 480 478 479 475 479 478 477 478 483 480 477 484 484 479 483 478 484 482 478 482 478 483 477 480 477 475 483 475
				478 479 480 481 480 478 481 485 479 477 477 481 480 480 478 483 475 483 479 480 481 480 479 480 480 481 477 474 478 485 481 479
				478 478 475 481 478 481 480 481 481 482 478 481 483 480 481 481 472 480 478 481 480 484 476 477 478 480 482 478 482 477 477 475
				478 482 478 480 482 480 480 480 478 479 478 481 481 479 480 480 480 480 483 478 481 481 480 480 480 478 483 477 473 477 484 478
				472 479 478 477 480 477 481 480 482 476 486 474 485 481 475 478 479 477 479 478 481 480 486 474 479 476 478 481 478 483 477 481
				478 483 484 478 480 483 481 481 478 479 479 481 482 478 477 481 479 477 481 483 480 484 478 481 481 480 481 481 476 475 473 477
				481 487 478 477 482 479 477 482 480 480 477 483 477 484 480 476 479 479 479 479 477 480 480 483 481 479 477 478 480 478 482 481
				478 481 482 486 478 481 481 482 484 478 479 481 483 484 478 478 480 479 475 485 482 478 484 478 475 483 480 480 483 475 476 481
				480 485 486 478 477 477 479 481 485 477 480 478 475 478 484 481 475 479 481 483 477 477 480 483 478 475 480 478 478 478 480 481
				480 478 480 482 484 477 482 481 480 480 478 480 480 484 484 478 480 479 480 474 486 483 478 483 482 479 483 479 478 481 475 481
				481 482 484 484 477 478 477 481 477 476 479 478 476 477 481 480 480 474 479 477 483 478 477 479 483 481 477 480 478 480 480 476
				483 477 478 480 483 484 480 481 485 479 478 478 480 482 483 484 480 480 480 479 474 484 481 478 477 479 480 480 481 477 483 480
				481 479 483 484 484 477 478 481 478 481 475 478 478 479 477 481 481 481 475 479 478 481 477 478 481 480 481 475 481 478 478 478
				480 483 478 478 480 481 480 478 476 477 480 477 481 481 480 484 481 478 479 479 480 474 486 484 474 483 477 481 478 478 479 477
				481 485 479 483 484 487 480 478 478 477 481 474 475 477 480 477 478 479 482 474 478 477 478 475 484 481 480 483 477 481 478 477
				477 480 481 478 476 481 483 482 477 481 477 480 477 482 481 480 476 479 479 481 478 479 474 484 478 477 483 475 482 478 477 479
				484 483 484 478 481 485 486 479 481 479 478 481 474 476 477 481 479 476 480 480 474 478 480 483 478 478 481 478 483 476 481 479
				476 484 480 481 479 477 477 483 476 480 481 477 479 475 483 481 480 477 479 480 481 478 479 473 484 474 478 484 475 481 479 478
				482 484 483 483 478 481 486 488 483 480 480 479 480 476 477 483 480 479 476 480 480 475 480 478 475 477 478 483 477 481 477 480
				482 486 483 480 481 477 475 479 480 475 480 482 475 478 477 481 484 481 477 478 479 480 479 477 477 479 476 480 486 476 484 480
				478 478 485 483 484 478 483 485 482 483 480 483 478 480 477 478 481 481 480 475 481 479 477 478 480 477 477 480 476 477 481 481
				482 480 482 481 481 481 477 476 479 483 477 483 482 473 480 477 487 478 481 477 478 478 481 481 483 475 483 474 480 487 476 477
				478 473 479 484 484 485 480 483 478 476 483 480 484 480 480 480 484 480 479 479 475 480 479 477 480 477 477 477 479 479 477 477
				480 481 482 475 482 479 483 477 478 482 481 477 484 481 472 480 483 486 478 482 478 478 478 480 483 483 474 480 476 480 484 477
				480 480 474 483 483 483 485 477 483 478 475 481 479 484 480 481 480 482 481 480 478 475 480 478 480 481 476 478 477 478 480 479
				477 476 483 481 478 482 481 481 482 474 481 479 478 485 482 474 478 483 486 477 480 481 479 478 476 477 485 476 479 476 478 481
				480 480 479 474 478 484 483 485 479 483 478 477 478 478 483 478 480 481 483 481 480 478 477 478 481 481 482 477 478 477 478 480
				476 477 478 482 479 479 483 480 477 481 475 481 481 479 484 483 483 478 484 486 478 481 479 479 480 481 481 484 475 482 477 481
				482 481 477 482 475 478 482 483 482 483 482 478 477 478 480 484 480 480 480 482 480 480 478 476 474 480 481 482 477 478 474 476
				481 482 477 480 484 478 479 485 478 477 482 475 483 478 478 484 478 484 478 484 486 477 481 479 478 481 480 479 478 476 482 481
				480 478 482 478 482 473 480 483 475 484 481 481 479 476 480 480 476 482 479 481 483 480 480 477 480 480 481 481 483 477 477 479
				479 480 483 481 480 483 479 483 483 483 478 482 475 481 480 481 476 477 483 477 483 486 477 477 480 480 484 483 477 483 475 474
				480 480 478 483 478 481 474 478 482 475 483 483 481 480 477 476 478 477 483 480 481 481 482 480 484 480 477 479 481 482 476 482
				483 482 480 483 477 479 480 477 479 484 482 477 484 475 481 476 479 475 476 484 477 483 484 476 481 479 480 483 481 477 484 477
				487 475 480 478 483 479 479 475 483 481 478 482 483 480 480 475 477 481 477 481 480 477 483 480 483 480 480 478 481 482 481 479
				483 480 483 480 481 474 477 481 480 478 479 483 477 483 477 483 478 480 476 477 483 476 484 484 485 483 478 479 481 479 478 478
				485 484 475 480 478 483 478 477 481 482 481 478 485 484 483 479 475 478 481 477 480 480 481 480 477 481 481 481 477 480 483 483
				480 480 479 483 480 480 474 477 484 484 480 480 481 477 484 477 484 476 480 475 477 482 476 483 479 486 483 478 479 479 476 477
				477 480 484 474 477 480 483 477 483 481 483 483 479 485 484 476 482 475 477 481 476 479 480 483 477 478 481 483 480 475 480 480
				477 479 479 479 483 480 480 473 480 484 480 480 481 481 478 481 481 484 473 477 478 477 484 477 481 481 486 482 480 478 481 482
				483 481 478 482 475 482 478 483 481 481 481 480 481 480 481 481 479 483 471 477 483 480 478 482 480 487 477 481 483 481 473 475
				479 479 477 481 477 480 480 482 477 477 483 483 478 481 480 479 478 482 483 472 477 483 476 483 482 482 481 484 483 480 477 480
				479 478 479 481 480 481 480 477 478 481 477 482 483 481 479 482 477 483 481 471 479 481 479 478 478 477 487 475 479 483 480 483
				482 480 480 479 481 479 481 478 480 477 477 480 474 478 478 479 478 477 483 479 475 479 476 478 479 484 481 477 481 477 477 475
				240 240 240>;

			PS_Config_Lmt_FW_CC_P = <
				66 57 62 62 64 64 63 64 63 64 63 63 63 63 64 66 66 57 62 62 64 63 63 64 63 64 63 63 63 63 63 66
				63 59 60 63 62 62 63 62 63 62 62 62 62 63 63 62 63 59 60 63 62 62 63 62 63 62 62 63 63 63 63 63
				63 63 57 62 62 63 63 63 63 63 64 63 63 63 63 63 63 63 57 62 62 63 63 63 63 63 63 63 63 63 63 63
				64 63 57 62 63 62 62 63 63 63 62 62 63 63 63 63 63 63 59 62 63 62 62 63 63 63 62 62 63 63 63 63
				64 63 63 57 62 62 64 63 63 63 63 64 63 63 63 63 64 63 63 57 62 62 64 63 63 63 63 64 63 63 63 64
				63 63 63 57 62 63 63 62 63 63 63 62 62 63 63 63 63 63 63 59 62 63 63 62 63 63 63 62 62 63 63 63
				63 63 63 63 57 62 62 64 63 63 63 63 64 63 63 63 63 63 63 63 57 62 62 64 63 63 63 63 64 63 63 64
				64 62 63 63 57 62 63 63 62 63 63 63 62 62 63 63 64 62 63 63 59 62 63 63 62 64 63 63 62 62 63 63
				63 63 63 63 63 57 62 62 63 63 63 63 63 64 63 64 63 63 63 63 63 57 62 63 63 63 63 63 63 64 63 63
				64 64 62 63 62 57 62 63 63 63 63 63 63 63 62 63 64 64 62 63 62 57 62 63 63 63 64 63 63 62 63 63
				63 62 63 63 63 63 57 62 64 63 63 63 63 63 64 64 63 63 63 63 63 63 57 62 64 63 63 63 63 63 64 63
				63 63 64 62 63 62 59 62 63 63 63 63 63 63 63 63 63 64 64 62 63 62 57 62 63 63 63 64 63 63 63 63
				64 62 62 63 63 63 63 57 63 64 63 63 63 63 64 64 64 63 63 62 63 63 63 57 63 64 63 63 63 63 63 64
				63 63 63 64 62 63 63 57 64 63 63 63 64 63 64 63 63 63 63 64 62 63 63 57 64 63 63 63 64 63 63 63
				63 63 62 62 63 63 63 63 63 63 64 63 63 63 63 64 63 63 62 63 62 63 63 63 63 63 64 63 63 63 63 63
				64 63 63 63 64 62 63 62 64 64 63 63 63 64 63 64 63 63 63 63 63 62 63 62 64 64 63 63 63 64 63 64
				64 63 63 62 62 63 64 63 63 63 63 64 64 63 63 63 63 63 63 62 63 62 63 63 64 63 63 64 63 63 63 63
				63 63 63 63 63 64 62 63 63 64 64 63 63 63 64 63 63 64 63 63 63 63 62 63 63 64 64 63 63 63 64 63
				64 64 63 63 62 62 63 63 64 64 63 63 64 64 63 63 64 64 63 63 62 63 63 63 64 64 63 63 64 63 63 63
				63 63 63 63 63 63 64 62 63 63 64 64 63 63 63 64 63 63 63 63 63 63 64 62 63 63 64 64 63 63 63 64
				63 64 64 63 63 62 62 63 64 64 64 63 64 64 64 63 63 64 63 63 63 62 63 62 63 64 64 63 63 64 63 63
				64 63 63 63 63 63 64 63 63 64 63 64 64 63 63 63 64 63 63 63 63 63 63 63 63 63 63 64 64 63 63 63
				63 63 64 64 63 63 62 62 64 64 64 64 63 64 64 64 63 63 64 63 63 63 62 63 64 64 64 64 63 63 64 64
				64 64 63 63 63 63 63 63 63 63 63 63 64 64 63 63 64 64 63 63 63 63 63 63 63 63 63 63 64 64 63 63
				64 63 63 64 64 63 63 62 63 64 64 64 64 63 64 64 64 63 63 64 63 63 63 62 63 64 64 64 64 63 63 64
				63 63 64 63 63 63 63 63 64 63 63 64 63 64 64 63 63 63 64 63 63 63 63 63 64 63 63 63 63 64 64 63
				64 64 63 63 64 64 63 63 63 64 64 64 64 64 63 64 64 64 63 63 64 63 63 63 63 63 64 64 64 64 63 64
				64 63 63 64 63 63 63 63 64 64 63 63 64 63 64 64 64 63 63 64 63 63 63 63 64 64 63 63 63 63 64 64
				64 64 64 63 63 64 64 63 63 64 64 66 64 64 64 63 64 64 64 63 63 64 63 63 63 63 63 64 64 64 64 63
				63 64 63 63 64 63 63 63 64 64 64 63 63 64 63 64 63 64 63 63 64 63 63 63 64 64 64 63 63 63 63 64
				63 64 64 64 63 63 64 64 64 64 64 64 66 64 64 64 64 64 64 64 63 63 64 63 64 63 63 63 64 64 64 64
				64 63 64 63 63 64 63 63 63 64 64 64 63 63 64 63 64 63 64 63 63 64 63 62 63 64 64 64 63 63 63 63
				64 63 64 64 64 63 63 64 63 64 64 64 64 66 64 64 64 64 64 64 64 63 63 64 64 64 63 63 63 64 64 64
				64 64 63 64 63 63 64 63 62 63 64 64 66 63 63 64 64 64 63 64 63 63 64 63 62 63 64 64 64 63 63 64
				63 63 63 64 64 64 63 63 59 64 64 64 64 64 66 64 64 64 64 64 64 64 63 63 59 64 64 63 63 63 64 64
				64 64 64 63 64 63 63 64 57 62 63 64 64 64 63 63 64 64 64 63 64 63 63 64 57 62 63 64 64 64 63 63
				64 63 63 63 64 64 64 63 64 59 64 64 64 64 64 66 64 64 64 64 64 64 64 63 64 59 64 64 64 63 63 66
				63 63 64 64 63 64 63 63 63 57 62 63 64 64 64 63 63 64 64 64 63 64 63 63 63 57 62 63 64 64 64 64
				64 64 63 63 63 64 64 64 63 64 59 64 64 64 64 64 64 64 64 64 64 64 64 64 63 64 59 64 64 63 63 64
				64 63 63 64 64 63 64 63 64 63 59 62 63 64 64 64 64 63 64 64 64 63 64 63 63 62 59 62 63 64 64 64
				64 64 64 63 63 63 64 64 63 63 64 59 64 64 64 64 64 64 64 63 64 63 64 64 63 63 64 59 64 64 63 64
				63 64 63 63 64 64 63 64 63 64 63 59 62 63 64 64 63 64 63 64 64 64 63 64 63 63 62 59 62 63 64 64
				66 64 64 64 63 63 63 64 63 63 63 64 59 64 64 64 64 64 64 64 63 64 64 64 63 63 63 64 59 64 64 64
				64 63 64 63 63 64 64 63 63 63 64 63 59 62 63 66 64 63 64 63 63 64 64 63 63 63 63 62 57 62 63 64
				63 64 64 64 64 63 63 63 63 63 63 63 64 59 64 64 63 64 64 64 64 63 64 63 63 63 63 63 64 59 64 64
				66 63 63 64 63 63 64 64 63 63 63 64 63 59 62 64 66 63 63 64 63 63 64 64 63 63 63 63 62 57 62 64
				63 63 64 64 63 64 63 63 63 63 63 63 63 64 59 64 63 63 64 64 64 64 63 64 63 63 63 63 63 64 59 64
				63 64 64 63 64 63 64 64 63 63 63 63 64 63 59 63 63 64 64 63 64 63 64 64 63 63 63 63 64 63 59 63
				314 314 314>;

			PS_Config_Lmt_FW_CC_N = <
				29 26 27 27 29 29 28 29 28 29 28 28 28 28 29 29 29 26 27 27 29 28 28 29 28 29 28 28 28 28 28 29
				28 26 27 28 27 27 28 27 28 27 27 27 27 28 28 27 28 26 27 28 27 27 28 27 28 27 27 28 28 28 28 28
				28 28 26 27 27 28 28 28 28 28 29 28 28 28 28 28 28 28 26 27 27 28 28 28 28 28 28 28 28 28 28 28
				29 28 26 27 28 27 27 28 28 28 27 27 28 28 28 28 28 28 26 27 28 27 27 28 28 28 27 27 28 28 28 28
				29 28 28 26 27 27 29 28 28 28 28 29 28 28 28 28 29 28 28 26 27 27 29 28 28 28 28 29 28 28 28 29
				28 28 28 26 27 28 28 27 28 28 28 27 27 28 28 28 28 28 28 26 27 28 28 27 28 28 28 27 27 28 28 28
				28 28 28 28 26 27 27 29 28 28 28 28 29 28 28 28 28 28 28 28 26 27 27 29 28 28 28 28 29 28 28 29
				29 27 28 28 26 27 28 28 27 28 28 28 27 27 28 28 29 27 28 28 26 27 28 28 27 29 28 28 27 27 28 28
				28 28 28 28 28 26 27 27 28 28 28 28 28 29 28 29 28 28 28 28 28 26 27 28 28 28 28 28 28 29 28 28
				29 29 27 28 27 26 27 28 28 28 28 28 28 28 27 28 29 29 27 28 27 26 27 28 28 28 29 28 28 27 28 28
				28 27 28 28 28 28 26 27 29 28 28 28 28 28 29 29 28 28 28 28 28 28 26 27 29 28 28 28 28 28 29 28
				28 28 29 27 28 27 26 27 28 28 28 28 28 28 28 28 28 29 29 27 28 27 26 27 28 28 28 29 28 28 28 28
				29 27 27 28 28 28 28 26 28 29 28 28 28 28 29 29 29 28 28 27 28 28 28 26 28 29 28 28 28 28 28 29
				28 28 28 29 27 28 28 26 29 28 28 28 29 28 29 28 28 28 28 29 27 28 28 26 29 28 28 28 29 28 28 28
				28 28 27 27 28 28 28 28 28 28 29 28 28 28 28 29 28 28 27 28 27 28 28 28 28 28 29 28 28 28 28 28
				29 28 28 28 29 27 28 27 29 29 28 28 28 29 28 29 28 28 28 28 28 27 28 27 29 29 28 28 28 29 28 29
				29 28 28 27 27 28 29 28 28 28 28 29 29 28 28 28 28 28 28 27 28 27 28 28 29 28 28 29 28 28 28 28
				28 28 28 28 28 29 27 28 28 29 29 28 28 28 29 28 28 29 28 28 28 28 27 28 28 29 29 28 28 28 29 28
				29 29 28 28 27 27 28 28 29 29 28 28 29 29 28 28 29 29 28 28 27 28 28 28 29 29 28 28 29 28 28 28
				28 28 28 28 28 28 29 27 28 28 29 29 28 28 28 29 28 28 28 28 28 28 29 27 28 28 29 29 28 28 28 29
				28 29 29 28 28 27 27 28 29 29 29 28 29 29 29 28 28 29 28 28 28 27 28 27 28 29 29 28 28 29 28 28
				29 28 28 28 28 28 29 28 28 29 28 29 29 28 28 28 29 28 28 28 28 28 28 28 28 28 28 29 29 28 28 28
				28 28 29 29 28 28 27 27 29 29 29 29 28 29 29 29 28 28 29 28 28 28 27 28 29 29 29 29 28 28 29 29
				29 29 28 28 28 28 28 28 28 28 28 28 29 29 28 28 29 29 28 28 28 28 28 28 28 28 28 28 29 29 28 28
				29 28 28 29 29 28 28 27 28 29 29 29 29 28 29 29 29 28 28 29 28 28 28 27 28 29 29 29 29 28 28 29
				28 28 29 28 28 28 28 28 29 28 28 29 28 29 29 28 28 28 29 28 28 28 28 28 29 28 28 28 28 29 29 28
				29 29 28 28 29 29 28 28 28 29 29 29 29 29 28 29 29 29 28 28 29 28 28 28 28 28 29 29 29 29 28 29
				29 28 28 29 28 28 28 28 29 29 28 28 29 28 29 29 29 28 28 29 28 28 28 28 29 29 28 28 28 28 29 29
				29 29 29 28 28 29 29 28 28 29 29 29 29 29 29 28 29 29 29 28 28 29 28 28 28 28 28 29 29 29 29 28
				28 29 28 28 29 28 28 28 29 29 29 28 28 29 28 29 28 29 28 28 29 28 28 28 29 29 29 28 28 28 28 29
				28 29 29 29 28 28 29 29 29 29 29 29 29 29 29 29 29 29 29 29 28 28 29 28 29 28 28 28 29 29 29 29
				29 28 29 28 28 29 28 28 28 29 29 29 28 28 29 28 29 28 29 28 28 29 28 27 28 29 29 29 28 28 28 28
				29 28 29 29 29 28 28 29 28 29 29 29 29 29 29 29 29 29 29 29 29 28 28 29 29 29 28 28 28 29 29 29
				29 29 28 29 28 28 29 28 27 28 29 29 29 28 28 29 29 29 28 29 28 28 29 28 27 28 29 29 29 28 28 29
				28 28 28 29 29 29 28 28 26 29 29 29 29 29 29 29 29 29 29 29 29 29 28 28 26 29 29 28 28 28 29 29
				29 29 29 28 29 28 28 29 26 27 28 29 29 29 28 28 29 29 29 28 29 28 28 29 26 27 28 29 29 29 28 28
				29 28 28 28 29 29 29 28 29 26 29 29 29 29 29 29 29 29 29 29 29 29 29 28 29 26 29 29 29 28 28 29
				28 28 29 29 28 29 28 28 28 26 27 28 29 29 29 28 28 29 29 29 28 29 28 28 28 26 27 28 29 29 29 29
				29 29 28 28 28 29 29 29 28 29 26 29 29 29 29 29 29 29 29 29 29 29 29 29 28 29 26 29 29 28 28 29
				29 28 28 29 29 28 29 28 29 28 26 27 28 29 29 29 29 28 29 29 29 28 29 28 28 27 26 27 28 29 29 29
				29 29 29 28 28 28 29 29 28 28 29 26 29 29 29 29 29 29 29 28 29 28 29 29 28 28 29 26 29 29 28 29
				28 29 28 28 29 29 28 29 28 29 28 26 27 28 29 29 28 29 28 29 29 29 28 29 28 28 27 26 27 28 29 29
				29 29 29 29 28 28 28 29 28 28 28 29 26 29 29 29 29 29 29 29 28 29 29 29 28 28 28 29 26 29 29 29
				29 28 29 28 28 29 29 28 28 28 29 28 26 27 28 29 29 28 29 28 28 29 29 28 28 28 28 27 26 27 28 29
				28 29 29 29 29 28 28 28 28 28 28 28 29 26 29 29 28 29 29 29 29 28 29 28 28 28 28 28 29 26 29 29
				29 28 28 29 28 28 29 29 28 28 28 29 28 26 27 29 29 28 28 29 28 28 29 29 28 28 28 28 27 26 27 29
				28 28 29 29 28 29 28 28 28 28 28 28 28 29 26 29 28 28 29 29 29 29 28 29 28 28 28 28 28 29 26 29
				28 29 29 28 29 28 29 29 28 28 28 28 29 28 26 28 28 29 29 28 29 28 29 29 28 28 28 28 29 28 26 28
				0 0 0>;

			PS_Config_Lmt_FW_Diff_P = <
				50 50 50 50 50 50 50 50 50 50 50 50 50 50 50 50 50 50 50 50 50 50 50 50 50 50 50 50 50 50 50 50
				50 50 50 50 50 50 50 50 50 50 50 50 50 50 50 50 50 50 50 50 50 50 50 50 50 50 50 50 50 50 50 50
				50 50 50 50 50 50 50 50 50 50 50 50 50 50 50 50 50 50 50 50 50 50 50 50 50 50 50 50 50 50 50 50
				50 50 50 50 50 50 50 50 50 50 50 50 50 50 50 50 50 50 50 50 50 50 50 50 50 50 50 50 50 50 50 50
				50 50 50 50 50 50 50 50 50 50 50 50 50 50 50 50 50 50 50 50 50 50 50 50 50 50 50 50 50 50 50 50
				50 50 50 50 50 50 50 50 50 50 50 50 50 50 50 50 50 50 50 50 50 50 50 50 50 50 50 50 50 50 50 50
				50 50 50 50 50 50 50 50 50 50 50 50 50 50 50 50 50 50 50 50 50 50 50 50 50 50 50 50 50 50 50 50
				50 50 50 50 50 50 50 50 50 50 50 50 50 50 50 50 50 50 50 50 50 50 50 50 50 50 50 50 50 50 50 50
				50 50 50 50 50 50 50 50 50 50 50 50 50 50 50 50 50 50 50 50 50 50 50 50 50 50 50 50 50 50 50 50
				50 50 50 50 50 50 50 50 50 50 50 50 50 50 50 50 50 50 50 50 50 50 50 50 50 50 50 50 50 50 50 50
				50 50 50 50 50 50 50 50 50 50 50 50 50 50 50 50 50 50 50 50 50 50 50 50 50 50 50 50 50 50 50 50
				50 50 50 50 50 50 50 50 50 50 50 50 50 50 50 50 50 50 50 50 50 50 50 50 50 50 50 50 50 50 50 50
				50 50 50 50 50 50 50 50 50 50 50 50 50 50 50 50 50 50 50 50 50 50 50 50 50 50 50 50 50 50 50 50
				50 50 50 50 50 50 50 50 50 50 50 50 50 50 50 50 50 50 50 50 50 50 50 50 50 50 50 50 50 50 50 50
				50 50 50 50 50 50 50 50 50 50 50 50 50 50 50 50 50 50 50 50 50 50 50 50 50 50 50 50 50 50 50 50
				50 50 50 50 50 50 50 50 50 50 50 50 50 50 50 50 50 50 50 50 50 50 50 50 50 50 50 50 50 50 50 50
				50 50 50 50 50 50 50 50 50 50 50 50 50 50 50 50 50 50 50 50 50 50 50 50 50 50 50 50 50 50 50 50
				50 50 50 50 50 50 50 50 50 50 50 50 50 50 50 50 50 50 50 50 50 50 50 50 50 50 50 50 50 50 50 50
				50 50 50 50 50 50 50 50 50 50 50 50 50 50 50 50 50 50 50 50 50 50 50 50 50 50 50 50 50 50 50 50
				50 50 50 50 50 50 50 50 50 50 50 50 50 50 50 50 50 50 50 50 50 50 50 50 50 50 50 50 50 50 50 50
				50 50 50 50 50 50 50 50 50 50 50 50 50 50 50 50 50 50 50 50 50 50 50 50 50 50 50 50 50 50 50 50
				50 50 50 50 50 50 50 50 50 50 50 50 50 50 50 50 50 50 50 50 50 50 50 50 50 50 50 50 50 50 50 50
				50 50 50 50 50 50 50 50 50 50 50 50 50 50 50 50 50 50 50 50 50 50 50 50 50 50 50 50 50 50 50 50
				50 50 50 50 50 50 50 50 50 50 50 50 50 50 50 50 50 50 50 50 50 50 50 50 50 50 50 50 50 50 50 50
				50 50 50 50 50 50 50 50 50 50 50 50 50 50 50 50 50 50 50 50 50 50 50 50 50 50 50 50 50 50 50 50
				50 50 50 50 50 50 50 50 50 50 50 50 50 50 50 50 50 50 50 50 50 50 50 50 50 50 50 50 50 50 50 50
				50 50 50 50 50 50 50 50 50 50 50 50 50 50 50 50 50 50 50 50 50 50 50 50 50 50 50 50 50 50 50 50
				50 50 50 50 50 50 50 50 50 50 50 50 50 50 50 50 50 50 50 50 50 50 50 50 50 50 50 50 50 50 50 50
				50 50 50 50 50 50 50 50 50 50 50 50 50 50 50 50 50 50 50 50 50 50 50 50 50 50 50 50 50 50 50 50
				50 50 50 50 50 50 50 50 50 50 50 50 50 50 50 50 50 50 50 50 50 50 50 50 50 50 50 50 50 50 50 50
				50 50 50 50 50 50 50 50 50 50 50 50 50 50 50 50 50 50 50 50 50 50 50 50 50 50 50 50 50 50 50 50
				50 50 50 50 50 50 50 50 50 50 50 50 50 50 50 50 50 50 50 50 50 50 50 50 50 50 50 50 50 50 50 50
				50 50 50 50 50 50 50 50 50 50 50 50 50 50 50 50 50 50 50 50 50 50 50 50 50 50 50 50 50 50 50 50
				50 50 50 50 50 50 50 50 50 50 50 50 50 50 50 50 50 50 50 50 50 50 50 50 50 50 50 50 50 50 50 50
				50 50 50 50 50 50 50 50 50 50 50 50 50 50 50 50 50 50 50 50 50 50 50 50 50 50 50 50 50 50 50 50
				50 50 50 50 50 50 50 50 50 50 50 50 50 50 50 50 50 50 50 50 50 50 50 50 50 50 50 50 50 50 50 50
				50 50 50 50 50 50 50 50 50 50 50 50 50 50 50 50 50 50 50 50 50 50 50 50 50 50 50 50 50 50 50 50
				50 50 50 50 50 50 50 50 50 50 50 50 50 50 50 50 50 50 50 50 50 50 50 50 50 50 50 50 50 50 50 50
				50 50 50 50 50 50 50 50 50 50 50 50 50 50 50 50 50 50 50 50 50 50 50 50 50 50 50 50 50 50 50 50
				50 50 50 50 50 50 50 50 50 50 50 50 50 50 50 50 50 50 50 50 50 50 50 50 50 50 50 50 50 50 50 50
				50 50 50 50 50 50 50 50 50 50 50 50 50 50 50 50 50 50 50 50 50 50 50 50 50 50 50 50 50 50 50 50
				50 50 50 50 50 50 50 50 50 50 50 50 50 50 50 50 50 50 50 50 50 50 50 50 50 50 50 50 50 50 50 50
				50 50 50 50 50 50 50 50 50 50 50 50 50 50 50 50 50 50 50 50 50 50 50 50 50 50 50 50 50 50 50 50
				50 50 50 50 50 50 50 50 50 50 50 50 50 50 50 50 50 50 50 50 50 50 50 50 50 50 50 50 50 50 50 50
				50 50 50 50 50 50 50 50 50 50 50 50 50 50 50 50 50 50 50 50 50 50 50 50 50 50 50 50 50 50 50 50
				50 50 50 50 50 50 50 50 50 50 50 50 50 50 50 50 50 50 50 50 50 50 50 50 50 50 50 50 50 50 50 50
				50 50 50 50 50 50 50 50 50 50 50 50 50 50 50 50 50 50 50 50 50 50 50 50 50 50 50 50 50 50 50 50
				50 50 50 50 50 50 50 50 50 50 50 50 50 50 50 50 50 50 50 50 50 50 50 50 50 50 50 50 50 50 50 50
				50 50 50>;

			PS_Config_Lmt_FW_Diff_N = <
				(-50) (-50) (-50) (-50) (-50) (-50) (-50) (-50) (-50) (-50) (-50) (-50) (-50) (-50) (-50) (-50) (-50) (-50) (-50) (-50) (-50) (-50) (-50) (-50) (-50) (-50) (-50) (-50) (-50) (-50) (-50) (-50)
				(-50) (-50) (-50) (-50) (-50) (-50) (-50) (-50) (-50) (-50) (-50) (-50) (-50) (-50) (-50) (-50) (-50) (-50) (-50) (-50) (-50) (-50) (-50) (-50) (-50) (-50) (-50) (-50) (-50) (-50) (-50) (-50)
				(-50) (-50) (-50) (-50) (-50) (-50) (-50) (-50) (-50) (-50) (-50) (-50) (-50) (-50) (-50) (-50) (-50) (-50) (-50) (-50) (-50) (-50) (-50) (-50) (-50) (-50) (-50) (-50) (-50) (-50) (-50) (-50)
				(-50) (-50) (-50) (-50) (-50) (-50) (-50) (-50) (-50) (-50) (-50) (-50) (-50) (-50) (-50) (-50) (-50) (-50) (-50) (-50) (-50) (-50) (-50) (-50) (-50) (-50) (-50) (-50) (-50) (-50) (-50) (-50)
				(-50) (-50) (-50) (-50) (-50) (-50) (-50) (-50) (-50) (-50) (-50) (-50) (-50) (-50) (-50) (-50) (-50) (-50) (-50) (-50) (-50) (-50) (-50) (-50) (-50) (-50) (-50) (-50) (-50) (-50) (-50) (-50)
				(-50) (-50) (-50) (-50) (-50) (-50) (-50) (-50) (-50) (-50) (-50) (-50) (-50) (-50) (-50) (-50) (-50) (-50) (-50) (-50) (-50) (-50) (-50) (-50) (-50) (-50) (-50) (-50) (-50) (-50) (-50) (-50)
				(-50) (-50) (-50) (-50) (-50) (-50) (-50) (-50) (-50) (-50) (-50) (-50) (-50) (-50) (-50) (-50) (-50) (-50) (-50) (-50) (-50) (-50) (-50) (-50) (-50) (-50) (-50) (-50) (-50) (-50) (-50) (-50)
				(-50) (-50) (-50) (-50) (-50) (-50) (-50) (-50) (-50) (-50) (-50) (-50) (-50) (-50) (-50) (-50) (-50) (-50) (-50) (-50) (-50) (-50) (-50) (-50) (-50) (-50) (-50) (-50) (-50) (-50) (-50) (-50)
				(-50) (-50) (-50) (-50) (-50) (-50) (-50) (-50) (-50) (-50) (-50) (-50) (-50) (-50) (-50) (-50) (-50) (-50) (-50) (-50) (-50) (-50) (-50) (-50) (-50) (-50) (-50) (-50) (-50) (-50) (-50) (-50)
				(-50) (-50) (-50) (-50) (-50) (-50) (-50) (-50) (-50) (-50) (-50) (-50) (-50) (-50) (-50) (-50) (-50) (-50) (-50) (-50) (-50) (-50) (-50) (-50) (-50) (-50) (-50) (-50) (-50) (-50) (-50) (-50)
				(-50) (-50) (-50) (-50) (-50) (-50) (-50) (-50) (-50) (-50) (-50) (-50) (-50) (-50) (-50) (-50) (-50) (-50) (-50) (-50) (-50) (-50) (-50) (-50) (-50) (-50) (-50) (-50) (-50) (-50) (-50) (-50)
				(-50) (-50) (-50) (-50) (-50) (-50) (-50) (-50) (-50) (-50) (-50) (-50) (-50) (-50) (-50) (-50) (-50) (-50) (-50) (-50) (-50) (-50) (-50) (-50) (-50) (-50) (-50) (-50) (-50) (-50) (-50) (-50)
				(-50) (-50) (-50) (-50) (-50) (-50) (-50) (-50) (-50) (-50) (-50) (-50) (-50) (-50) (-50) (-50) (-50) (-50) (-50) (-50) (-50) (-50) (-50) (-50) (-50) (-50) (-50) (-50) (-50) (-50) (-50) (-50)
				(-50) (-50) (-50) (-50) (-50) (-50) (-50) (-50) (-50) (-50) (-50) (-50) (-50) (-50) (-50) (-50) (-50) (-50) (-50) (-50) (-50) (-50) (-50) (-50) (-50) (-50) (-50) (-50) (-50) (-50) (-50) (-50)
				(-50) (-50) (-50) (-50) (-50) (-50) (-50) (-50) (-50) (-50) (-50) (-50) (-50) (-50) (-50) (-50) (-50) (-50) (-50) (-50) (-50) (-50) (-50) (-50) (-50) (-50) (-50) (-50) (-50) (-50) (-50) (-50)
				(-50) (-50) (-50) (-50) (-50) (-50) (-50) (-50) (-50) (-50) (-50) (-50) (-50) (-50) (-50) (-50) (-50) (-50) (-50) (-50) (-50) (-50) (-50) (-50) (-50) (-50) (-50) (-50) (-50) (-50) (-50) (-50)
				(-50) (-50) (-50) (-50) (-50) (-50) (-50) (-50) (-50) (-50) (-50) (-50) (-50) (-50) (-50) (-50) (-50) (-50) (-50) (-50) (-50) (-50) (-50) (-50) (-50) (-50) (-50) (-50) (-50) (-50) (-50) (-50)
				(-50) (-50) (-50) (-50) (-50) (-50) (-50) (-50) (-50) (-50) (-50) (-50) (-50) (-50) (-50) (-50) (-50) (-50) (-50) (-50) (-50) (-50) (-50) (-50) (-50) (-50) (-50) (-50) (-50) (-50) (-50) (-50)
				(-50) (-50) (-50) (-50) (-50) (-50) (-50) (-50) (-50) (-50) (-50) (-50) (-50) (-50) (-50) (-50) (-50) (-50) (-50) (-50) (-50) (-50) (-50) (-50) (-50) (-50) (-50) (-50) (-50) (-50) (-50) (-50)
				(-50) (-50) (-50) (-50) (-50) (-50) (-50) (-50) (-50) (-50) (-50) (-50) (-50) (-50) (-50) (-50) (-50) (-50) (-50) (-50) (-50) (-50) (-50) (-50) (-50) (-50) (-50) (-50) (-50) (-50) (-50) (-50)
				(-50) (-50) (-50) (-50) (-50) (-50) (-50) (-50) (-50) (-50) (-50) (-50) (-50) (-50) (-50) (-50) (-50) (-50) (-50) (-50) (-50) (-50) (-50) (-50) (-50) (-50) (-50) (-50) (-50) (-50) (-50) (-50)
				(-50) (-50) (-50) (-50) (-50) (-50) (-50) (-50) (-50) (-50) (-50) (-50) (-50) (-50) (-50) (-50) (-50) (-50) (-50) (-50) (-50) (-50) (-50) (-50) (-50) (-50) (-50) (-50) (-50) (-50) (-50) (-50)
				(-50) (-50) (-50) (-50) (-50) (-50) (-50) (-50) (-50) (-50) (-50) (-50) (-50) (-50) (-50) (-50) (-50) (-50) (-50) (-50) (-50) (-50) (-50) (-50) (-50) (-50) (-50) (-50) (-50) (-50) (-50) (-50)
				(-50) (-50) (-50) (-50) (-50) (-50) (-50) (-50) (-50) (-50) (-50) (-50) (-50) (-50) (-50) (-50) (-50) (-50) (-50) (-50) (-50) (-50) (-50) (-50) (-50) (-50) (-50) (-50) (-50) (-50) (-50) (-50)
				(-50) (-50) (-50) (-50) (-50) (-50) (-50) (-50) (-50) (-50) (-50) (-50) (-50) (-50) (-50) (-50) (-50) (-50) (-50) (-50) (-50) (-50) (-50) (-50) (-50) (-50) (-50) (-50) (-50) (-50) (-50) (-50)
				(-50) (-50) (-50) (-50) (-50) (-50) (-50) (-50) (-50) (-50) (-50) (-50) (-50) (-50) (-50) (-50) (-50) (-50) (-50) (-50) (-50) (-50) (-50) (-50) (-50) (-50) (-50) (-50) (-50) (-50) (-50) (-50)
				(-50) (-50) (-50) (-50) (-50) (-50) (-50) (-50) (-50) (-50) (-50) (-50) (-50) (-50) (-50) (-50) (-50) (-50) (-50) (-50) (-50) (-50) (-50) (-50) (-50) (-50) (-50) (-50) (-50) (-50) (-50) (-50)
				(-50) (-50) (-50) (-50) (-50) (-50) (-50) (-50) (-50) (-50) (-50) (-50) (-50) (-50) (-50) (-50) (-50) (-50) (-50) (-50) (-50) (-50) (-50) (-50) (-50) (-50) (-50) (-50) (-50) (-50) (-50) (-50)
				(-50) (-50) (-50) (-50) (-50) (-50) (-50) (-50) (-50) (-50) (-50) (-50) (-50) (-50) (-50) (-50) (-50) (-50) (-50) (-50) (-50) (-50) (-50) (-50) (-50) (-50) (-50) (-50) (-50) (-50) (-50) (-50)
				(-50) (-50) (-50) (-50) (-50) (-50) (-50) (-50) (-50) (-50) (-50) (-50) (-50) (-50) (-50) (-50) (-50) (-50) (-50) (-50) (-50) (-50) (-50) (-50) (-50) (-50) (-50) (-50) (-50) (-50) (-50) (-50)
				(-50) (-50) (-50) (-50) (-50) (-50) (-50) (-50) (-50) (-50) (-50) (-50) (-50) (-50) (-50) (-50) (-50) (-50) (-50) (-50) (-50) (-50) (-50) (-50) (-50) (-50) (-50) (-50) (-50) (-50) (-50) (-50)
				(-50) (-50) (-50) (-50) (-50) (-50) (-50) (-50) (-50) (-50) (-50) (-50) (-50) (-50) (-50) (-50) (-50) (-50) (-50) (-50) (-50) (-50) (-50) (-50) (-50) (-50) (-50) (-50) (-50) (-50) (-50) (-50)
				(-50) (-50) (-50) (-50) (-50) (-50) (-50) (-50) (-50) (-50) (-50) (-50) (-50) (-50) (-50) (-50) (-50) (-50) (-50) (-50) (-50) (-50) (-50) (-50) (-50) (-50) (-50) (-50) (-50) (-50) (-50) (-50)
				(-50) (-50) (-50) (-50) (-50) (-50) (-50) (-50) (-50) (-50) (-50) (-50) (-50) (-50) (-50) (-50) (-50) (-50) (-50) (-50) (-50) (-50) (-50) (-50) (-50) (-50) (-50) (-50) (-50) (-50) (-50) (-50)
				(-50) (-50) (-50) (-50) (-50) (-50) (-50) (-50) (-50) (-50) (-50) (-50) (-50) (-50) (-50) (-50) (-50) (-50) (-50) (-50) (-50) (-50) (-50) (-50) (-50) (-50) (-50) (-50) (-50) (-50) (-50) (-50)
				(-50) (-50) (-50) (-50) (-50) (-50) (-50) (-50) (-50) (-50) (-50) (-50) (-50) (-50) (-50) (-50) (-50) (-50) (-50) (-50) (-50) (-50) (-50) (-50) (-50) (-50) (-50) (-50) (-50) (-50) (-50) (-50)
				(-50) (-50) (-50) (-50) (-50) (-50) (-50) (-50) (-50) (-50) (-50) (-50) (-50) (-50) (-50) (-50) (-50) (-50) (-50) (-50) (-50) (-50) (-50) (-50) (-50) (-50) (-50) (-50) (-50) (-50) (-50) (-50)
				(-50) (-50) (-50) (-50) (-50) (-50) (-50) (-50) (-50) (-50) (-50) (-50) (-50) (-50) (-50) (-50) (-50) (-50) (-50) (-50) (-50) (-50) (-50) (-50) (-50) (-50) (-50) (-50) (-50) (-50) (-50) (-50)
				(-50) (-50) (-50) (-50) (-50) (-50) (-50) (-50) (-50) (-50) (-50) (-50) (-50) (-50) (-50) (-50) (-50) (-50) (-50) (-50) (-50) (-50) (-50) (-50) (-50) (-50) (-50) (-50) (-50) (-50) (-50) (-50)
				(-50) (-50) (-50) (-50) (-50) (-50) (-50) (-50) (-50) (-50) (-50) (-50) (-50) (-50) (-50) (-50) (-50) (-50) (-50) (-50) (-50) (-50) (-50) (-50) (-50) (-50) (-50) (-50) (-50) (-50) (-50) (-50)
				(-50) (-50) (-50) (-50) (-50) (-50) (-50) (-50) (-50) (-50) (-50) (-50) (-50) (-50) (-50) (-50) (-50) (-50) (-50) (-50) (-50) (-50) (-50) (-50) (-50) (-50) (-50) (-50) (-50) (-50) (-50) (-50)
				(-50) (-50) (-50) (-50) (-50) (-50) (-50) (-50) (-50) (-50) (-50) (-50) (-50) (-50) (-50) (-50) (-50) (-50) (-50) (-50) (-50) (-50) (-50) (-50) (-50) (-50) (-50) (-50) (-50) (-50) (-50) (-50)
				(-50) (-50) (-50) (-50) (-50) (-50) (-50) (-50) (-50) (-50) (-50) (-50) (-50) (-50) (-50) (-50) (-50) (-50) (-50) (-50) (-50) (-50) (-50) (-50) (-50) (-50) (-50) (-50) (-50) (-50) (-50) (-50)
				(-50) (-50) (-50) (-50) (-50) (-50) (-50) (-50) (-50) (-50) (-50) (-50) (-50) (-50) (-50) (-50) (-50) (-50) (-50) (-50) (-50) (-50) (-50) (-50) (-50) (-50) (-50) (-50) (-50) (-50) (-50) (-50)
				(-50) (-50) (-50) (-50) (-50) (-50) (-50) (-50) (-50) (-50) (-50) (-50) (-50) (-50) (-50) (-50) (-50) (-50) (-50) (-50) (-50) (-50) (-50) (-50) (-50) (-50) (-50) (-50) (-50) (-50) (-50) (-50)
				(-50) (-50) (-50) (-50) (-50) (-50) (-50) (-50) (-50) (-50) (-50) (-50) (-50) (-50) (-50) (-50) (-50) (-50) (-50) (-50) (-50) (-50) (-50) (-50) (-50) (-50) (-50) (-50) (-50) (-50) (-50) (-50)
				(-50) (-50) (-50) (-50) (-50) (-50) (-50) (-50) (-50) (-50) (-50) (-50) (-50) (-50) (-50) (-50) (-50) (-50) (-50) (-50) (-50) (-50) (-50) (-50) (-50) (-50) (-50) (-50) (-50) (-50) (-50) (-50)
				(-50) (-50) (-50) (-50) (-50) (-50) (-50) (-50) (-50) (-50) (-50) (-50) (-50) (-50) (-50) (-50) (-50) (-50) (-50) (-50) (-50) (-50) (-50) (-50) (-50) (-50) (-50) (-50) (-50) (-50) (-50) (-50)
				(-50) (-50) (-50)>;

			PS_Config_Lmt_PenTipX_FW_Raw_P = <
				380 380 380 380 380 380 380 380 380 380 380 380 380 380 380 380 380 380 380 380 380 380 380 380 380 380 380 380 380 380 380 380
				380 380 380 380 380 380 380 380 380 380 380 380 380 380 380 380 380 380 380 380 380 380 380 380 380 380 380 380 380 380 380 380
				380 380 380 380 380 380 380 380 380 380 380 380 380 380 380 380 380 380 380 380 380 380 380 380 380 380 380 380 380 380 380 380
				380 380 380 380 380 380 380 380 380 380 380 380 380 380 380 380 380 380 380 380 380 380 380 380 380 380 380 380 380 380 380 380
				380 380 380 380 380 380 380 380 380 380 380 380 380 380 380 380 380 380 380 380 380 380 380 380 380 380 380 380 380 380 380 380
				380 380 380 380 380 380 380 380 380 380 380 380 380 380 380 380 380 380 380 380 380 380 380 380 380 380 380 380 380 380 380 380>;

			PS_Config_Lmt_PenTipX_FW_Raw_N = <
				0 0 0 0 0 0 0 0 0 0 0 0 0 0 0 0 0 0 0 0 0 0 0 0 0 0 0 0 0 0 0 0
				0 0 0 0 0 0 0 0 0 0 0 0 0 0 0 0 0 0 0 0 0 0 0 0 0 0 0 0 0 0 0 0
				0 0 0 0 0 0 0 0 0 0 0 0 0 0 0 0 0 0 0 0 0 0 0 0 0 0 0 0 0 0 0 0
				0 0 0 0 0 0 0 0 0 0 0 0 0 0 0 0 0 0 0 0 0 0 0 0 0 0 0 0 0 0 0 0
				0 0 0 0 0 0 0 0 0 0 0 0 0 0 0 0 0 0 0 0 0 0 0 0 0 0 0 0 0 0 0 0
				0 0 0 0 0 0 0 0 0 0 0 0 0 0 0 0 0 0 0 0 0 0 0 0 0 0 0 0 0 0 0 0>;

			PS_Config_Lmt_PenTipY_FW_Raw_P = <
				380 380 380 380
				380 380 380 380
				380 380 380 380
				380 380 380 380
				380 380 380 380
				380 380 380 380
				380 380 380 380
				380 380 380 380
				380 380 380 380
				380 380 380 380
				380 380 380 380
				380 380 380 380
				380 380 380 380
				380 380 380 380
				380 380 380 380
				380 380 380 380
				380 380 380 380
				380 380 380 380
				380 380 380 380
				380 380 380 380
				380 380 380 380
				380 380 380 380
				380 380 380 380
				380 380 380 380
				380 380 380 380
				380 380 380 380
				380 380 380 380
				380 380 380 380
				380 380 380 380
				380 380 380 380
				380 380 380 380
				380 380 380 380
				380 380 380 380
				380 380 380 380
				380 380 380 380
				380 380 380 380
				380 380 380 380
				380 380 380 380
				380 380 380 380
				380 380 380 380
				380 380 380 380
				380 380 380 380
				380 380 380 380
				380 380 380 380
				380 380 380 380
				380 380 380 380
				380 380 380 380
				380 380 380 380>;

			PS_Config_Lmt_PenTipY_FW_Raw_N = <
				0 0 0 0
				0 0 0 0
				0 0 0 0
				0 0 0 0
				0 0 0 0
				0 0 0 0
				0 0 0 0
				0 0 0 0
				0 0 0 0
				0 0 0 0
				0 0 0 0
				0 0 0 0
				0 0 0 0
				0 0 0 0
				0 0 0 0
				0 0 0 0
				0 0 0 0
				0 0 0 0
				0 0 0 0
				0 0 0 0
				0 0 0 0
				0 0 0 0
				0 0 0 0
				0 0 0 0
				0 0 0 0
				0 0 0 0
				0 0 0 0
				0 0 0 0
				0 0 0 0
				0 0 0 0
				0 0 0 0
				0 0 0 0
				0 0 0 0
				0 0 0 0
				0 0 0 0
				0 0 0 0
				0 0 0 0
				0 0 0 0
				0 0 0 0
				0 0 0 0
				0 0 0 0
				0 0 0 0
				0 0 0 0
				0 0 0 0
				0 0 0 0
				0 0 0 0
				0 0 0 0
				0 0 0 0>;

			PS_Config_Lmt_PenRingX_FW_Raw_P = <
				380 380 380 380 380 380 380 380 380 380 380 380 380 380 380 380 380 380 380 380 380 380 380 380 380 380 380 380 380 380 380 380
				380 380 380 380 380 380 380 380 380 380 380 380 380 380 380 380 380 380 380 380 380 380 380 380 380 380 380 380 380 380 380 380
				380 380 380 380 380 380 380 380 380 380 380 380 380 380 380 380 380 380 380 380 380 380 380 380 380 380 380 380 380 380 380 380
				380 380 380 380 380 380 380 380 380 380 380 380 380 380 380 380 380 380 380 380 380 380 380 380 380 380 380 380 380 380 380 380
				380 380 380 380 380 380 380 380 380 380 380 380 380 380 380 380 380 380 380 380 380 380 380 380 380 380 380 380 380 380 380 380
				380 380 380 380 380 380 380 380 380 380 380 380 380 380 380 380 380 380 380 380 380 380 380 380 380 380 380 380 380 380 380 380>;

			PS_Config_Lmt_PenRingX_FW_Raw_N = <
				0 0 0 0 0 0 0 0 0 0 0 0 0 0 0 0 0 0 0 0 0 0 0 0 0 0 0 0 0 0 0 0
				0 0 0 0 0 0 0 0 0 0 0 0 0 0 0 0 0 0 0 0 0 0 0 0 0 0 0 0 0 0 0 0
				0 0 0 0 0 0 0 0 0 0 0 0 0 0 0 0 0 0 0 0 0 0 0 0 0 0 0 0 0 0 0 0
				0 0 0 0 0 0 0 0 0 0 0 0 0 0 0 0 0 0 0 0 0 0 0 0 0 0 0 0 0 0 0 0
				0 0 0 0 0 0 0 0 0 0 0 0 0 0 0 0 0 0 0 0 0 0 0 0 0 0 0 0 0 0 0 0
				0 0 0 0 0 0 0 0 0 0 0 0 0 0 0 0 0 0 0 0 0 0 0 0 0 0 0 0 0 0 0 0>;

			PS_Config_Lmt_PenRingY_FW_Raw_P = <
				380 380 380 380
				380 380 380 380
				380 380 380 380
				380 380 380 380
				380 380 380 380
				380 380 380 380
				380 380 380 380
				380 380 380 380
				380 380 380 380
				380 380 380 380
				380 380 380 380
				380 380 380 380
				380 380 380 380
				380 380 380 380
				380 380 380 380
				380 380 380 380
				380 380 380 380
				380 380 380 380
				380 380 380 380
				380 380 380 380
				380 380 380 380
				380 380 380 380
				380 380 380 380
				380 380 380 380
				380 380 380 380
				380 380 380 380
				380 380 380 380
				380 380 380 380
				380 380 380 380
				380 380 380 380
				380 380 380 380
				380 380 380 380
				380 380 380 380
				380 380 380 380
				380 380 380 380
				380 380 380 380
				380 380 380 380
				380 380 380 380
				380 380 380 380
				380 380 380 380
				380 380 380 380
				380 380 380 380
				380 380 380 380
				380 380 380 380
				380 380 380 380
				380 380 380 380
				380 380 380 380
				380 380 380 380>;

			PS_Config_Lmt_PenRingY_FW_Raw_N = <
				0 0 0 0
				0 0 0 0
				0 0 0 0
				0 0 0 0
				0 0 0 0
				0 0 0 0
				0 0 0 0
				0 0 0 0
				0 0 0 0
				0 0 0 0
				0 0 0 0
				0 0 0 0
				0 0 0 0
				0 0 0 0
				0 0 0 0
				0 0 0 0
				0 0 0 0
				0 0 0 0
				0 0 0 0
				0 0 0 0
				0 0 0 0
				0 0 0 0
				0 0 0 0
				0 0 0 0
				0 0 0 0
				0 0 0 0
				0 0 0 0
				0 0 0 0
				0 0 0 0
				0 0 0 0
				0 0 0 0
				0 0 0 0
				0 0 0 0
				0 0 0 0
				0 0 0 0
				0 0 0 0
				0 0 0 0
				0 0 0 0
				0 0 0 0
				0 0 0 0
				0 0 0 0
				0 0 0 0
				0 0 0 0
				0 0 0 0
				0 0 0 0
				0 0 0 0
				0 0 0 0
				0 0 0 0>;

			PS_Config_Lmt_PenTipX_FW_Diff_P = <
				580 580 580 580 580 580 580 580 580 580 580 580 580 580 580 580 580 580 580 580 580 580 580 580 580 580 580 580 580 580 580 580
				580 580 580 580 580 580 580 580 580 580 580 580 580 580 580 580 580 580 580 580 580 580 580 580 580 580 580 580 580 580 580 580
				580 580 580 580 580 580 580 580 580 580 580 580 580 580 580 580 580 580 580 580 580 580 580 580 580 580 580 580 580 580 580 580
				580 580 580 580 580 580 580 580 580 580 580 580 580 580 580 580 580 580 580 580 580 580 580 580 580 580 580 580 580 580 580 580
				580 580 580 580 580 580 580 580 580 580 580 580 580 580 580 580 580 580 580 580 580 580 580 580 580 580 580 580 580 580 580 580
				580 580 580 580 580 580 580 580 580 580 580 580 580 580 580 580 580 580 580 580 580 580 580 580 580 580 580 580 580 580 580 580>;

			PS_Config_Lmt_PenTipX_FW_Diff_N = <
				(-580) (-580) (-580) (-580) (-580) (-580) (-580) (-580) (-580) (-580) (-580) (-580) (-580) (-580) (-580) (-580) (-580) (-580) (-580) (-580) (-580) (-580) (-580) (-580) (-580) (-580) (-580) (-580) (-580) (-580) (-580) (-580)
				(-580) (-580) (-580) (-580) (-580) (-580) (-580) (-580) (-580) (-580) (-580) (-580) (-580) (-580) (-580) (-580) (-580) (-580) (-580) (-580) (-580) (-580) (-580) (-580) (-580) (-580) (-580) (-580) (-580) (-580) (-580) (-580)
				(-580) (-580) (-580) (-580) (-580) (-580) (-580) (-580) (-580) (-580) (-580) (-580) (-580) (-580) (-580) (-580) (-580) (-580) (-580) (-580) (-580) (-580) (-580) (-580) (-580) (-580) (-580) (-580) (-580) (-580) (-580) (-580)
				(-580) (-580) (-580) (-580) (-580) (-580) (-580) (-580) (-580) (-580) (-580) (-580) (-580) (-580) (-580) (-580) (-580) (-580) (-580) (-580) (-580) (-580) (-580) (-580) (-580) (-580) (-580) (-580) (-580) (-580) (-580) (-580)
				(-580) (-580) (-580) (-580) (-580) (-580) (-580) (-580) (-580) (-580) (-580) (-580) (-580) (-580) (-580) (-580) (-580) (-580) (-580) (-580) (-580) (-580) (-580) (-580) (-580) (-580) (-580) (-580) (-580) (-580) (-580) (-580)
				(-580) (-580) (-580) (-580) (-580) (-580) (-580) (-580) (-580) (-580) (-580) (-580) (-580) (-580) (-580) (-580) (-580) (-580) (-580) (-580) (-580) (-580) (-580) (-580) (-580) (-580) (-580) (-580) (-580) (-580) (-580) (-580)>;

			PS_Config_Lmt_PenTipY_FW_Diff_P = <
				580 580 580 580
				580 580 580 580
				580 580 580 580
				580 580 580 580
				580 580 580 580
				580 580 580 580
				580 580 580 580
				580 580 580 580
				580 580 580 580
				580 580 580 580
				580 580 580 580
				580 580 580 580
				580 580 580 580
				580 580 580 580
				580 580 580 580
				580 580 580 580
				580 580 580 580
				580 580 580 580
				580 580 580 580
				580 580 580 580
				580 580 580 580
				580 580 580 580
				580 580 580 580
				580 580 580 580
				580 580 580 580
				580 580 580 580
				580 580 580 580
				580 580 580 580
				580 580 580 580
				580 580 580 580
				580 580 580 580
				580 580 580 580
				580 580 580 580
				580 580 580 580
				580 580 580 580
				580 580 580 580
				580 580 580 580
				580 580 580 580
				580 580 580 580
				580 580 580 580
				580 580 580 580
				580 580 580 580
				580 580 580 580
				580 580 580 580
				580 580 580 580
				580 580 580 580
				580 580 580 580
				580 580 580 580>;

			PS_Config_Lmt_PenTipY_FW_Diff_N = <
				(-580) (-580) (-580) (-580)
				(-580) (-580) (-580) (-580)
				(-580) (-580) (-580) (-580)
				(-580) (-580) (-580) (-580)
				(-580) (-580) (-580) (-580)
				(-580) (-580) (-580) (-580)
				(-580) (-580) (-580) (-580)
				(-580) (-580) (-580) (-580)
				(-580) (-580) (-580) (-580)
				(-580) (-580) (-580) (-580)
				(-580) (-580) (-580) (-580)
				(-580) (-580) (-580) (-580)
				(-580) (-580) (-580) (-580)
				(-580) (-580) (-580) (-580)
				(-580) (-580) (-580) (-580)
				(-580) (-580) (-580) (-580)
				(-580) (-580) (-580) (-580)
				(-580) (-580) (-580) (-580)
				(-580) (-580) (-580) (-580)
				(-580) (-580) (-580) (-580)
				(-580) (-580) (-580) (-580)
				(-580) (-580) (-580) (-580)
				(-580) (-580) (-580) (-580)
				(-580) (-580) (-580) (-580)
				(-580) (-580) (-580) (-580)
				(-580) (-580) (-580) (-580)
				(-580) (-580) (-580) (-580)
				(-580) (-580) (-580) (-580)
				(-580) (-580) (-580) (-580)
				(-580) (-580) (-580) (-580)
				(-580) (-580) (-580) (-580)
				(-580) (-580) (-580) (-580)
				(-580) (-580) (-580) (-580)
				(-580) (-580) (-580) (-580)
				(-580) (-580) (-580) (-580)
				(-580) (-580) (-580) (-580)
				(-580) (-580) (-580) (-580)
				(-580) (-580) (-580) (-580)
				(-580) (-580) (-580) (-580)
				(-580) (-580) (-580) (-580)
				(-580) (-580) (-580) (-580)
				(-580) (-580) (-580) (-580)
				(-580) (-580) (-580) (-580)
				(-580) (-580) (-580) (-580)
				(-580) (-580) (-580) (-580)
				(-580) (-580) (-580) (-580)
				(-580) (-580) (-580) (-580)
				(-580) (-580) (-580) (-580)>;

			PS_Config_Lmt_PenRingX_FW_Diff_P = <
				580 580 580 580 580 580 580 580 580 580 580 580 580 580 580 580 580 580 580 580 580 580 580 580 580 580 580 580 580 580 580 580
				580 580 580 580 580 580 580 580 580 580 580 580 580 580 580 580 580 580 580 580 580 580 580 580 580 580 580 580 580 580 580 580
				580 580 580 580 580 580 580 580 580 580 580 580 580 580 580 580 580 580 580 580 580 580 580 580 580 580 580 580 580 580 580 580
				580 580 580 580 580 580 580 580 580 580 580 580 580 580 580 580 580 580 580 580 580 580 580 580 580 580 580 580 580 580 580 580
				580 580 580 580 580 580 580 580 580 580 580 580 580 580 580 580 580 580 580 580 580 580 580 580 580 580 580 580 580 580 580 580
				580 580 580 580 580 580 580 580 580 580 580 580 580 580 580 580 580 580 580 580 580 580 580 580 580 580 580 580 580 580 580 580>;

			PS_Config_Lmt_PenRingX_FW_Diff_N = <
				(-580) (-580) (-580) (-580) (-580) (-580) (-580) (-580) (-580) (-580) (-580) (-580) (-580) (-580) (-580) (-580) (-580) (-580) (-580) (-580) (-580) (-580) (-580) (-580) (-580) (-580) (-580) (-580) (-580) (-580) (-580) (-580)
				(-580) (-580) (-580) (-580) (-580) (-580) (-580) (-580) (-580) (-580) (-580) (-580) (-580) (-580) (-580) (-580) (-580) (-580) (-580) (-580) (-580) (-580) (-580) (-580) (-580) (-580) (-580) (-580) (-580) (-580) (-580) (-580)
				(-580) (-580) (-580) (-580) (-580) (-580) (-580) (-580) (-580) (-580) (-580) (-580) (-580) (-580) (-580) (-580) (-580) (-580) (-580) (-580) (-580) (-580) (-580) (-580) (-580) (-580) (-580) (-580) (-580) (-580) (-580) (-580)
				(-580) (-580) (-580) (-580) (-580) (-580) (-580) (-580) (-580) (-580) (-580) (-580) (-580) (-580) (-580) (-580) (-580) (-580) (-580) (-580) (-580) (-580) (-580) (-580) (-580) (-580) (-580) (-580) (-580) (-580) (-580) (-580)
				(-580) (-580) (-580) (-580) (-580) (-580) (-580) (-580) (-580) (-580) (-580) (-580) (-580) (-580) (-580) (-580) (-580) (-580) (-580) (-580) (-580) (-580) (-580) (-580) (-580) (-580) (-580) (-580) (-580) (-580) (-580) (-580)
				(-580) (-580) (-580) (-580) (-580) (-580) (-580) (-580) (-580) (-580) (-580) (-580) (-580) (-580) (-580) (-580) (-580) (-580) (-580) (-580) (-580) (-580) (-580) (-580) (-580) (-580) (-580) (-580) (-580) (-580) (-580) (-580)>;

			PS_Config_Lmt_PenRingY_FW_Diff_P = <
				580 580 580 580
				580 580 580 580
				580 580 580 580
				580 580 580 580
				580 580 580 580
				580 580 580 580
				580 580 580 580
				580 580 580 580
				580 580 580 580
				580 580 580 580
				580 580 580 580
				580 580 580 580
				580 580 580 580
				580 580 580 580
				580 580 580 580
				580 580 580 580
				580 580 580 580
				580 580 580 580
				580 580 580 580
				580 580 580 580
				580 580 580 580
				580 580 580 580
				580 580 580 580
				580 580 580 580
				580 580 580 580
				580 580 580 580
				580 580 580 580
				580 580 580 580
				580 580 580 580
				580 580 580 580
				580 580 580 580
				580 580 580 580
				580 580 580 580
				580 580 580 580
				580 580 580 580
				580 580 580 580
				580 580 580 580
				580 580 580 580
				580 580 580 580
				580 580 580 580
				580 580 580 580
				580 580 580 580
				580 580 580 580
				580 580 580 580
				580 580 580 580
				580 580 580 580
				580 580 580 580
				580 580 580 580>;

			PS_Config_Lmt_PenRingY_FW_Diff_N = <
				(-580) (-580) (-580) (-580)
				(-580) (-580) (-580) (-580)
				(-580) (-580) (-580) (-580)
				(-580) (-580) (-580) (-580)
				(-580) (-580) (-580) (-580)
				(-580) (-580) (-580) (-580)
				(-580) (-580) (-580) (-580)
				(-580) (-580) (-580) (-580)
				(-580) (-580) (-580) (-580)
				(-580) (-580) (-580) (-580)
				(-580) (-580) (-580) (-580)
				(-580) (-580) (-580) (-580)
				(-580) (-580) (-580) (-580)
				(-580) (-580) (-580) (-580)
				(-580) (-580) (-580) (-580)
				(-580) (-580) (-580) (-580)
				(-580) (-580) (-580) (-580)
				(-580) (-580) (-580) (-580)
				(-580) (-580) (-580) (-580)
				(-580) (-580) (-580) (-580)
				(-580) (-580) (-580) (-580)
				(-580) (-580) (-580) (-580)
				(-580) (-580) (-580) (-580)
				(-580) (-580) (-580) (-580)
				(-580) (-580) (-580) (-580)
				(-580) (-580) (-580) (-580)
				(-580) (-580) (-580) (-580)
				(-580) (-580) (-580) (-580)
				(-580) (-580) (-580) (-580)
				(-580) (-580) (-580) (-580)
				(-580) (-580) (-580) (-580)
				(-580) (-580) (-580) (-580)
				(-580) (-580) (-580) (-580)
				(-580) (-580) (-580) (-580)
				(-580) (-580) (-580) (-580)
				(-580) (-580) (-580) (-580)
				(-580) (-580) (-580) (-580)
				(-580) (-580) (-580) (-580)
				(-580) (-580) (-580) (-580)
				(-580) (-580) (-580) (-580)
				(-580) (-580) (-580) (-580)
				(-580) (-580) (-580) (-580)
				(-580) (-580) (-580) (-580)
				(-580) (-580) (-580) (-580)
				(-580) (-580) (-580) (-580)
				(-580) (-580) (-580) (-580)
				(-580) (-580) (-580) (-580)
				(-580) (-580) (-580) (-580)>;

			PS_Config_Diff_Test_Frame = <50>;
		};
	};
};
&touch {
	compatible = "mediatek,touch-himax";
	tpd-resolution = <1200 2000>;
	use-tpd-button = <0>;
	tpd-key-num = <10>;
	tpd-key-local= <139 172 158 0>;
	tpd-key-dim-local = <60 850 50 30
		180 850 50 30 300 850 50 30 420 850 50 30>;
	tpd-max-touch-num = <5>;
	tpd-filter-enable = <1>;
	tpd-filter-pixel-density = <124>;
	tpd-filter-custom-prameters = <0 0 0 0 0 0 0 0 0 0 0 0>;
	tpd-filter-custom-speed = <0 0 0>;
	pinctrl-names = "default", "state_eint_as_int", "state_eint_output0",
		"state_eint_output1", "state_rst_output0", "state_rst_output1";
	pinctrl-0 = <&ctp_pins_default>;
	pinctrl-1 = <&ctp_pins_eint_as_int>;
	pinctrl-2 = <&ctp_pins_eint_output0>;
	pinctrl-3 = <&ctp_pins_eint_output1>;
	pinctrl-4 = <&ctp_pins_rst_output0>;
	pinctrl-5 = <&ctp_pins_rst_output1>;
	status = "okay";

};
/* TOUCH end */


&aud_gpio_i2s1_off {
	pins_cmd_dat {
		pinmux = <PINMUX_GPIO32__FUNC_GPIO32>,
			 <PINMUX_GPIO34__FUNC_GPIO34>,
			 <PINMUX_GPIO31__FUNC_GPIO31>;
	};
};

&aud_gpio_i2s1_on {
	pins_cmd_dat {
		pinmux = <PINMUX_GPIO32__FUNC_I2S1_LRCK>,
			 <PINMUX_GPIO34__FUNC_I2S1_DO>,
			 <PINMUX_GPIO31__FUNC_I2S1_BCK>;
	};
};

&aud_gpio_i2s2_off {
	pins_cmd_dat {
		pinmux = <PINMUX_GPIO33__FUNC_GPIO33>;
	};
};

&aud_gpio_i2s2_on {
	pins_cmd_dat {
		pinmux = <PINMUX_GPIO33__FUNC_I2S2_DI>;
	};
};

#include <yoga11/cust.dtsi>
#include "mediatek/cust_mt6785_camera_yaga.dtsi"
/*End of this file, DO NOT ADD ANYTHING HERE*/
